AUTOSAR XML (schema 4-2-1)
standard types defined: boolean, float32, uint8, boolean_CompuMethod, boolean_DataConstr, float32_DataConstr, uint8_DataConstr
package /ComponentTypes
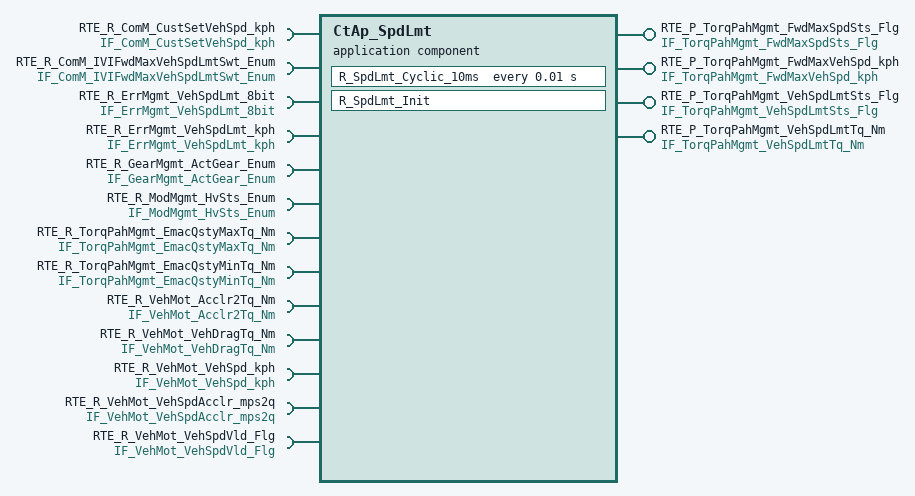
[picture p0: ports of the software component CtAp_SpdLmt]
  application sw component type CtAp_SpdLmt
    4 x provide port:
      RTE_P_TorqPahMgmt_FwdMaxSpdSts_Flg: nonqueued-sender-com-spec{data-element=tec_TorqPahMgmt_FwdMaxSpdSts_Flg, init-value=0}, provided-interface=IF_TorqPahMgmt_FwdMaxSpdSts_Flg
      RTE_P_TorqPahMgmt_FwdMaxVehSpd_kph: nonqueued-sender-com-spec{data-element=tec_TorqPahMgmt_FwdMaxVehSpd_kph, init-value=0}, provided-interface=IF_TorqPahMgmt_FwdMaxVehSpd_kph
      RTE_P_TorqPahMgmt_VehSpdLmtSts_Flg: nonqueued-sender-com-spec{data-element=tec_TorqPahMgmt_VehSpdLmtSts_Flg, init-value=0}, provided-interface=IF_TorqPahMgmt_VehSpdLmtSts_Flg
      RTE_P_TorqPahMgmt_VehSpdLmtTq_Nm: nonqueued-sender-com-spec{data-element=tec_TorqPahMgmt_VehSpdLmtTq_Nm, init-value=0}, provided-interface=IF_TorqPahMgmt_VehSpdLmtTq_Nm
    13 x require port:
      RTE_R_ComM_CustSetVehSpd_kph: nonqueued-receiver-com-spec{data-element=tec_ComM_IVISetFwdVehSpd_kph, filter=data-filter-type=ALWAYS, init-value=0}, required-interface=IF_ComM_CustSetVehSpd_kph
      RTE_R_ComM_IVIFwdMaxVehSpdLmtSwt_Enum: nonqueued-receiver-com-spec{data-element=tec_ComM_IVIFwdMaxVehSpdLmtSwt_Enum, filter=data-filter-type=ALWAYS, init-value=0}, required-interface=IF_ComM_IVIFwdMaxVehSpdLmtSwt_Enum
      RTE_R_ErrMgmt_VehSpdLmt_8bit: nonqueued-receiver-com-spec{data-element=tec_ErrMgmt_VehSpdLmt_8bit, filter=data-filter-type=ALWAYS, init-value=0}, required-interface=IF_ErrMgmt_VehSpdLmt_8bit
      RTE_R_ErrMgmt_VehSpdLmt_kph: nonqueued-receiver-com-spec{data-element=tec_ErrMgmt_VehSpdLmt_kph, filter=data-filter-type=ALWAYS, init-value=0}, required-interface=IF_ErrMgmt_VehSpdLmt_kph
      RTE_R_GearMgmt_ActGear_Enum: nonqueued-receiver-com-spec{data-element=tec_GearMgmt_ActGear_Enum, filter=data-filter-type=ALWAYS, init-value=0}, required-interface=IF_GearMgmt_ActGear_Enum
      RTE_R_ModMgmt_HvSts_Enum: nonqueued-receiver-com-spec{data-element=tec_ModMgmt_HvSts_Enum, filter=data-filter-type=ALWAYS, init-value=0}, required-interface=IF_ModMgmt_HvSts_Enum
      RTE_R_TorqPahMgmt_EmacQstyMaxTq_Nm: nonqueued-receiver-com-spec{data-element=tec_TorqPahMgmt_EmacQstyMaxTq_Nm, filter=data-filter-type=ALWAYS, init-value=0}, required-interface=IF_TorqPahMgmt_EmacQstyMaxTq_Nm
      RTE_R_TorqPahMgmt_EmacQstyMinTq_Nm: nonqueued-receiver-com-spec{data-element=tec_TorqPahMgmt_EmacQstyMinTq_Nm, filter=data-filter-type=ALWAYS, init-value=0}, required-interface=IF_TorqPahMgmt_EmacQstyMinTq_Nm
      RTE_R_VehMot_Acclr2Tq_Nm: nonqueued-receiver-com-spec{data-element=tec_VehMot_Acclr2Tq_Nm, filter=data-filter-type=ALWAYS, init-value=0}, required-interface=IF_VehMot_Acclr2Tq_Nm
      RTE_R_VehMot_VehDragTq_Nm: nonqueued-receiver-com-spec{data-element=tec_VehMot_VehDragTq_Nm, filter=data-filter-type=ALWAYS, init-value=0}, required-interface=IF_VehMot_VehDragTq_Nm
      RTE_R_VehMot_VehSpd_kph: nonqueued-receiver-com-spec{data-element=tec_VehMot_VehSpd_kph, filter=data-filter-type=ALWAYS, init-value=0}, required-interface=IF_VehMot_VehSpd_kph
      RTE_R_VehMot_VehSpdAcclr_mps2q: nonqueued-receiver-com-spec{data-element=tec_VehMot_VehSpdAcclr_mps2q, filter=data-filter-type=ALWAYS, init-value=0}, required-interface=IF_VehMot_VehSpdAcclr_mps2q
      RTE_R_VehMot_VehSpdVld_Flg: nonqueued-receiver-com-spec{data-element=tec_VehMot_VehSpdVld_Flg, filter=data-filter-type=ALWAYS, init-value=0}, required-interface=IF_VehMot_VehSpdVld_Flg
    behavior CtAp_SpdLmt_InternalBehavior
      timing event TMT_R_SpdLmt_Cyclic_10ms: start-on-event=R_SpdLmt_Cyclic_10ms, period=0.01
      init event CtAp_TorqLmt_InitEvent: start-on-event=R_SpdLmt_Init
      runnable R_SpdLmt_Cyclic_10ms
        data-receive-point-by-arguments:
          13 x access:
            REC_RTE_R_ComM_CustSetVehSpd_kph_tec_ComM_IVISetFwdVehSpd_kph: accessed-variable=RTE_R_ComM_CustSetVehSpd_kph.tec_ComM_IVISetFwdVehSpd_kph
            REC_RTE_R_ComM_IVIFwdMaxVehSpdLmtSwt_Enum_tec_ComM_IVIFwdMaxVehSpdLmtSwt_Enum: accessed-variable=RTE_R_ComM_IVIFwdMaxVehSpdLmtSwt_Enum.tec_ComM_IVIFwdMaxVehSpdLmtSwt_Enum
            REC_RTE_R_ErrMgmt_VehSpdLmt_8bit_tec_ErrMgmt_VehSpdLmt_8bit: accessed-variable=RTE_R_ErrMgmt_VehSpdLmt_8bit.tec_ErrMgmt_VehSpdLmt_8bit
            REC_RTE_R_ErrMgmt_VehSpdLmt_kph_tec_ErrMgmt_VehSpdLmt_kph: accessed-variable=RTE_R_ErrMgmt_VehSpdLmt_kph.tec_ErrMgmt_VehSpdLmt_kph
            REC_RTE_R_GearMgmt_ActGear_Enum_tec_GearMgmt_ActGear_Enum: accessed-variable=RTE_R_GearMgmt_ActGear_Enum.tec_GearMgmt_ActGear_Enum
            REC_RTE_R_ModMgmt_HvSts_Enum_tec_ModMgmt_HvSts_Enum: accessed-variable=RTE_R_ModMgmt_HvSts_Enum.tec_ModMgmt_HvSts_Enum
            REC_RTE_R_VehMot_Acclr2Tq_Nm_tec_VehMot_Acclr2Tq_Nm: accessed-variable=RTE_R_VehMot_Acclr2Tq_Nm.tec_VehMot_Acclr2Tq_Nm
            REC_RTE_R_VehMot_VehDragTq_Nm_tec_VehMot_VehDragTq_Nm: accessed-variable=RTE_R_VehMot_VehDragTq_Nm.tec_VehMot_VehDragTq_Nm
            REC_RTE_R_VehMot_VehSpd_kph_tec_VehMot_VehSpd_kph: accessed-variable=RTE_R_VehMot_VehSpd_kph.tec_VehMot_VehSpd_kph
            REC_RTE_R_VehMot_VehSpdAcclr_mps2q_tec_VehMot_VehSpdAcclr_mps2q: accessed-variable=RTE_R_VehMot_VehSpdAcclr_mps2q.tec_VehMot_VehSpdAcclr_mps2q
            REC_RTE_R_VehMot_VehSpdVld_Flg_tec_VehMot_VehSpdVld_Flg: accessed-variable=RTE_R_VehMot_VehSpdVld_Flg.tec_VehMot_VehSpdVld_Flg
            SEND_RTE_P_TorqPahMgmt_EmacQstyMaxTq_Nm_tec_TorqPahMgmt_EmacQstyMaxTq_Nm: accessed-variable=RTE_R_TorqPahMgmt_EmacQstyMaxTq_Nm.tec_TorqPahMgmt_EmacQstyMaxTq_Nm
            SEND_RTE_P_TorqPahMgmt_EmacQstyMinTq_Nm_tec_TorqPahMgmt_EmacQstyMinTq_Nm: accessed-variable=RTE_R_TorqPahMgmt_EmacQstyMinTq_Nm.tec_TorqPahMgmt_EmacQstyMinTq_Nm
        data-send-points:
          4 x access:
            SEND_RTE_P_TorqPahMgmt_FwdMaxSpdSts_Flg_tec_TorqPahMgmt_FwdMaxSpdSts_Flg: accessed-variable=RTE_P_TorqPahMgmt_FwdMaxSpdSts_Flg.tec_TorqPahMgmt_FwdMaxSpdSts_Flg
            SEND_RTE_P_TorqPahMgmt_FwdMaxVehSpd_kph_tec_TorqPahMgmt_FwdMaxVehSpd_kph: accessed-variable=RTE_P_TorqPahMgmt_FwdMaxVehSpd_kph.tec_TorqPahMgmt_FwdMaxVehSpd_kph
            SEND_RTE_P_TorqPahMgmt_VehSpdLmtSts_Flg_tec_TorqPahMgmt_VehSpdLmtSts_Flg: accessed-variable=RTE_P_TorqPahMgmt_VehSpdLmtSts_Flg.tec_TorqPahMgmt_VehSpdLmtSts_Flg
            SEND_RTE_P_TorqPahMgmt_VehSpdLmtTq_Nm_tec_TorqPahMgmt_VehSpdLmtTq_Nm: accessed-variable=RTE_P_TorqPahMgmt_VehSpdLmtTq_Nm.tec_TorqPahMgmt_VehSpdLmtTq_Nm
      runnable R_SpdLmt_Init
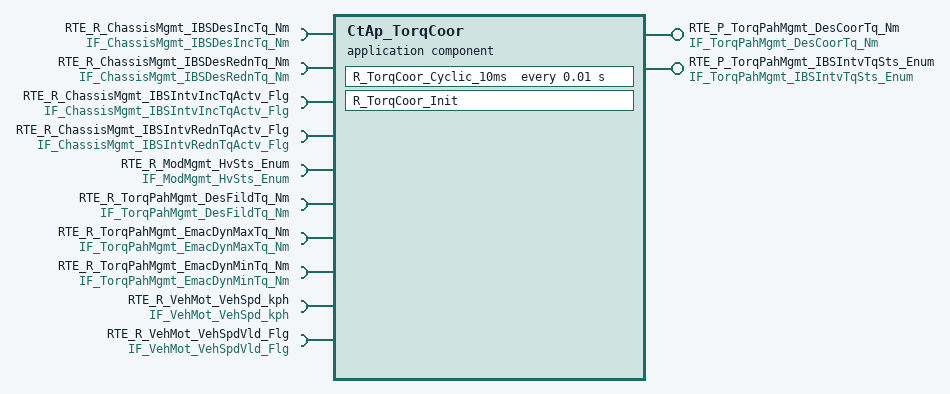
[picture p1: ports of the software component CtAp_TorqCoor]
  application sw component type CtAp_TorqCoor
    provide port RTE_P_TorqPahMgmt_DesCoorTq_Nm: nonqueued-sender-com-spec{data-element=tec_TorqPahMgmt_DesCoorTq_Nm, init-value=0}, provided-interface=IF_TorqPahMgmt_DesCoorTq_Nm
    provide port RTE_P_TorqPahMgmt_IBSIntvTqSts_Enum: nonqueued-sender-com-spec{data-element=tec_TorqPahMgmt_IBSIntvTqSts_Enum, init-value=0}, provided-interface=IF_TorqPahMgmt_IBSIntvTqSts_Enum
    10 x require port:
      RTE_R_ChassisMgmt_IBSDesIncTq_Nm: nonqueued-receiver-com-spec{data-element=tec_ChassisMgmt_IBSDesIncTq_Nm, filter=data-filter-type=ALWAYS, init-value=0}, required-interface=IF_ChassisMgmt_IBSDesIncTq_Nm
      RTE_R_ChassisMgmt_IBSDesRednTq_Nm: nonqueued-receiver-com-spec{data-element=tec_ChassisMgmt_IBSDesRednTq_Nm, filter=data-filter-type=ALWAYS, init-value=0}, required-interface=IF_ChassisMgmt_IBSDesRednTq_Nm
      RTE_R_ChassisMgmt_IBSIntvIncTqActv_Flg: nonqueued-receiver-com-spec{data-element=tec_ChassisMgmt_IBSIntvIncTqActv_Flg, filter=data-filter-type=ALWAYS, init-value=0}, required-interface=IF_ChassisMgmt_IBSIntvIncTqActv_Flg
      RTE_R_ChassisMgmt_IBSIntvRednTqActv_Flg: nonqueued-receiver-com-spec{data-element=tec_ChassisMgmt_IBSIntvRednTqActv_Flg, filter=data-filter-type=ALWAYS, init-value=0}, required-interface=IF_ChassisMgmt_IBSIntvRednTqActv_Flg
      RTE_R_ModMgmt_HvSts_Enum: nonqueued-receiver-com-spec{data-element=tec_ModMgmt_HvSts_Enum, filter=data-filter-type=ALWAYS, init-value=0}, required-interface=IF_ModMgmt_HvSts_Enum
      RTE_R_TorqPahMgmt_DesFildTq_Nm: nonqueued-receiver-com-spec{data-element=tec_TorqPahMgmt_DesFildTq_Nm, filter=data-filter-type=ALWAYS, init-value=0}, required-interface=IF_TorqPahMgmt_DesFildTq_Nm
      RTE_R_TorqPahMgmt_EmacDynMaxTq_Nm: nonqueued-receiver-com-spec{data-element=tec_TorqPahMgmt_EmacDynMaxTq_Nm, filter=data-filter-type=ALWAYS, init-value=0}, required-interface=IF_TorqPahMgmt_EmacDynMaxTq_Nm
      RTE_R_TorqPahMgmt_EmacDynMinTq_Nm: nonqueued-receiver-com-spec{data-element=tec_TorqPahMgmt_EmacDynMinTq_Nm, filter=data-filter-type=ALWAYS, init-value=0}, required-interface=IF_TorqPahMgmt_EmacDynMinTq_Nm
      RTE_R_VehMot_VehSpd_kph: nonqueued-receiver-com-spec{data-element=tec_VehMot_VehSpd_kph, filter=data-filter-type=ALWAYS, init-value=0}, required-interface=IF_VehMot_VehSpd_kph
      RTE_R_VehMot_VehSpdVld_Flg: nonqueued-receiver-com-spec{data-element=tec_VehMot_VehSpdVld_Flg, filter=data-filter-type=ALWAYS, init-value=0}, required-interface=IF_VehMot_VehSpdVld_Flg
    behavior CtAp_TorqCoor_InternalBehavior
      timing event TMT_R_TorqCoor_Cyclic_10ms: start-on-event=R_TorqCoor_Cyclic_10ms, period=0.01
      init event CtAp_TorqCoor_InitEvent: start-on-event=R_TorqCoor_Init
      runnable R_TorqCoor_Cyclic_10ms
        data-receive-point-by-arguments:
          10 x access:
            REC_RTE_R_ChassisMgmt_IBSDesIncTq_Nm_tec_ChassisMgmt_IBSDesIncTq_Nm: accessed-variable=RTE_R_ChassisMgmt_IBSDesIncTq_Nm.tec_ChassisMgmt_IBSDesIncTq_Nm
            REC_RTE_R_ChassisMgmt_IBSDesRednTq_Nm_tec_ChassisMgmt_IBSDesRednTq_Nm: accessed-variable=RTE_R_ChassisMgmt_IBSDesRednTq_Nm.tec_ChassisMgmt_IBSDesRednTq_Nm
            REC_RTE_R_ChassisMgmt_IBSIntvIncTqActv_Flg_tec_ChassisMgmt_IBSIntvIncTqActv_Flg: accessed-variable=RTE_R_ChassisMgmt_IBSIntvIncTqActv_Flg.tec_ChassisMgmt_IBSIntvIncTqActv_Flg
            REC_RTE_R_ChassisMgmt_IBSIntvRednTqActv_Flg_tec_ChassisMgmt_IBSIntvRednTqActv_Flg: accessed-variable=RTE_R_ChassisMgmt_IBSIntvRednTqActv_Flg.tec_ChassisMgmt_IBSIntvRednTqActv_Flg
            REC_RTE_R_ModMgmt_HvSts_Enum_tec_ModMgmt_HvSts_Enum: accessed-variable=RTE_R_ModMgmt_HvSts_Enum.tec_ModMgmt_HvSts_Enum
            REC_RTE_R_TorqPahMgmt_DesFildTq_Nm_tec_TorqPahMgmt_DesFildTq_Nm: accessed-variable=RTE_R_TorqPahMgmt_DesFildTq_Nm.tec_TorqPahMgmt_DesFildTq_Nm
            REC_RTE_R_TorqPahMgmt_EmacDynMaxTq_Nm_tec_TorqPahMgmt_EmacDynMaxTq_Nm: accessed-variable=RTE_R_TorqPahMgmt_EmacDynMaxTq_Nm.tec_TorqPahMgmt_EmacDynMaxTq_Nm
            REC_RTE_R_TorqPahMgmt_EmacDynMinTq_Nm_tec_TorqPahMgmt_EmacDynMinTq_Nm: accessed-variable=RTE_R_TorqPahMgmt_EmacDynMinTq_Nm.tec_TorqPahMgmt_EmacDynMinTq_Nm
            REC_RTE_R_VehMot_VehSpd_kph_tec_VehMot_VehSpd_kph: accessed-variable=RTE_R_VehMot_VehSpd_kph.tec_VehMot_VehSpd_kph
            REC_RTE_R_VehMot_VehSpdVld_Flg_tec_VehMot_VehSpdVld_Flg: accessed-variable=RTE_R_VehMot_VehSpdVld_Flg.tec_VehMot_VehSpdVld_Flg
        data-send-points:
          access SEND_RTE_P_TorqPahMgmt_DesCoorTq_Nm_tec_TorqPahMgmt_DesCoorTq_Nm: accessed-variable=RTE_P_TorqPahMgmt_DesCoorTq_Nm.tec_TorqPahMgmt_DesCoorTq_Nm
          access SEND_RTE_P_TorqPahMgmt_IBSIntvTqSts_Enum_tec_TorqPahMgmt_IBSIntvTqSts_Enum: accessed-variable=RTE_P_TorqPahMgmt_IBSIntvTqSts_Enum.tec_TorqPahMgmt_IBSIntvTqSts_Enum
      runnable R_TorqCoor_Init
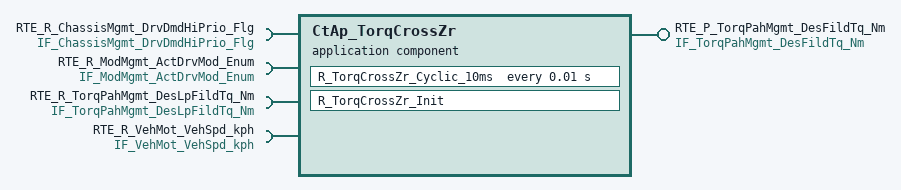
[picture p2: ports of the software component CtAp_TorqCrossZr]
  application sw component type CtAp_TorqCrossZr
    provide port RTE_P_TorqPahMgmt_DesFildTq_Nm: nonqueued-sender-com-spec{data-element=tec_TorqPahMgmt_DesFildTq_Nm, init-value=0}, provided-interface=IF_TorqPahMgmt_DesFildTq_Nm
    4 x require port:
      RTE_R_ChassisMgmt_DrvDmdHiPrio_Flg: nonqueued-receiver-com-spec{data-element=tec_ChassisMgmt_DrvDmdHiPrio_Flg, filter=data-filter-type=ALWAYS, init-value=0}, required-interface=IF_ChassisMgmt_DrvDmdHiPrio_Flg
      RTE_R_ModMgmt_ActDrvMod_Enum: nonqueued-receiver-com-spec{data-element=tec_ModMgmt_ActDrvMod_Enum, filter=data-filter-type=ALWAYS, init-value=0}, required-interface=IF_ModMgmt_ActDrvMod_Enum
      RTE_R_TorqPahMgmt_DesLpFildTq_Nm: nonqueued-receiver-com-spec{data-element=tec_TorqPahMgmt_DesLpFildTq_Nm, filter=data-filter-type=ALWAYS, init-value=0}, required-interface=IF_TorqPahMgmt_DesLpFildTq_Nm
      RTE_R_VehMot_VehSpd_kph: nonqueued-receiver-com-spec{data-element=tec_VehMot_VehSpd_kph, filter=data-filter-type=ALWAYS, init-value=0}, required-interface=IF_VehMot_VehSpd_kph
    behavior CtAp_TorqCrossZr_InternalBehavior
      timing event TMT_R_TorqCrossZr_Cyclic_10ms: start-on-event=R_TorqCrossZr_Cyclic_10ms, period=0.01
      init event CtAp_TorqCrossZr_InitEvent: start-on-event=R_TorqCrossZr_Init
      runnable R_TorqCrossZr_Cyclic_10ms
        data-receive-point-by-arguments:
          4 x access:
            REC_RTE_R_ChassisMgmt_DrvDmdHiPrio_Flg_tec_ChassisMgmt_DrvDmdHiPrio_Flg: accessed-variable=RTE_R_ChassisMgmt_DrvDmdHiPrio_Flg.tec_ChassisMgmt_DrvDmdHiPrio_Flg
            REC_RTE_R_ModMgmt_ActDrvMod_Enum_tec_ModMgmt_ActDrvMod_Enum: accessed-variable=RTE_R_ModMgmt_ActDrvMod_Enum.tec_ModMgmt_ActDrvMod_Enum
            REC_RTE_R_TorqPahMgmt_DesLpFildTq_Nm_tec_TorqPahMgmt_DesLpFildTq_Nm: accessed-variable=RTE_R_TorqPahMgmt_DesLpFildTq_Nm.tec_TorqPahMgmt_DesLpFildTq_Nm
            REC_RTE_R_VehMot_VehSpd_kph_tec_VehMot_VehSpd_kph: accessed-variable=RTE_R_VehMot_VehSpd_kph.tec_VehMot_VehSpd_kph
        data-send-points:
          access SEND_RTE_P_TorqPahMgmt_DesFildTq_Nm_tec_TorqPahMgmt_DesFildTq_Nm: accessed-variable=RTE_P_TorqPahMgmt_DesFildTq_Nm.tec_TorqPahMgmt_DesFildTq_Nm
      runnable R_TorqCrossZr_Init
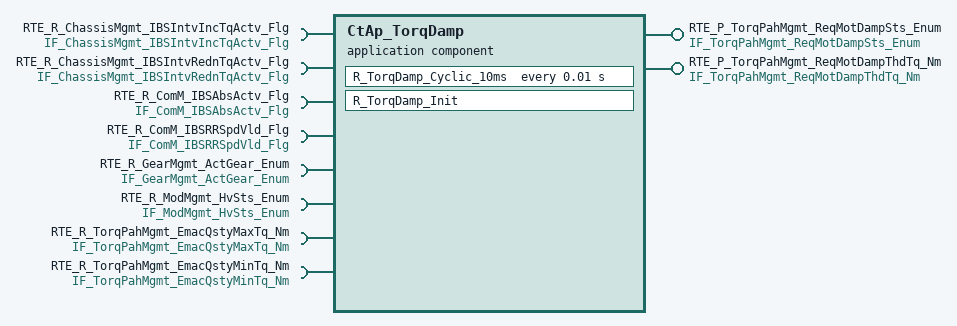
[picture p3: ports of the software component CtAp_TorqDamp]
  application sw component type CtAp_TorqDamp
    provide port RTE_P_TorqPahMgmt_ReqMotDampSts_Enum: nonqueued-sender-com-spec=data-element=tec_TorqPahMgmt_ReqMotDampSts_Enum, provided-interface=IF_TorqPahMgmt_ReqMotDampSts_Enum
    provide port RTE_P_TorqPahMgmt_ReqMotDampThdTq_Nm: nonqueued-sender-com-spec=data-element=tec_TorqPahMgmt_ReqMotDampThdTq_Nm, provided-interface=IF_TorqPahMgmt_ReqMotDampThdTq_Nm
    8 x require port:
      RTE_R_ChassisMgmt_IBSIntvIncTqActv_Flg: nonqueued-receiver-com-spec{data-element=tec_ChassisMgmt_IBSIntvIncTqActv_Flg, filter=data-filter-type=ALWAYS}, required-interface=IF_ChassisMgmt_IBSIntvIncTqActv_Flg
      RTE_R_ChassisMgmt_IBSIntvRednTqActv_Flg: nonqueued-receiver-com-spec{data-element=tec_ChassisMgmt_IBSIntvRednTqActv_Flg, filter=data-filter-type=ALWAYS}, required-interface=IF_ChassisMgmt_IBSIntvRednTqActv_Flg
      RTE_R_ComM_IBSAbsActv_Flg: nonqueued-receiver-com-spec{data-element=tec_ComM_IBSAbsActv_Flg, filter=data-filter-type=ALWAYS}, required-interface=IF_ComM_IBSAbsActv_Flg
      RTE_R_ComM_IBSRRSpdVld_Flg: nonqueued-receiver-com-spec{data-element=tec_ComM_IBSRRSpdVld_Flg, filter=data-filter-type=ALWAYS}, required-interface=IF_ComM_IBSRRSpdVld_Flg
      RTE_R_GearMgmt_ActGear_Enum: nonqueued-receiver-com-spec{data-element=tec_GearMgmt_ActGear_Enum, filter=data-filter-type=ALWAYS}, required-interface=IF_GearMgmt_ActGear_Enum
      RTE_R_ModMgmt_HvSts_Enum: nonqueued-receiver-com-spec{data-element=tec_ModMgmt_HvSts_Enum, filter=data-filter-type=ALWAYS}, required-interface=IF_ModMgmt_HvSts_Enum
      RTE_R_TorqPahMgmt_EmacQstyMaxTq_Nm: nonqueued-receiver-com-spec{data-element=tec_TorqPahMgmt_EmacQstyMaxTq_Nm, filter=data-filter-type=ALWAYS}, required-interface=IF_TorqPahMgmt_EmacQstyMaxTq_Nm
      RTE_R_TorqPahMgmt_EmacQstyMinTq_Nm: nonqueued-receiver-com-spec{data-element=tec_TorqPahMgmt_EmacQstyMinTq_Nm, filter=data-filter-type=ALWAYS}, required-interface=IF_TorqPahMgmt_EmacQstyMinTq_Nm
    behavior CtAp_TorqDamp_InternalBehavior
      timing event TMT_R_TorqDamp_Cyclic_10ms: start-on-event=R_TorqDamp_Cyclic_10ms, period=0.01
      init event CtAp_TorqDamp_InitEvent: start-on-event=R_TorqDamp_Init
      runnable R_TorqDamp_Cyclic_10ms
        data-receive-point-by-arguments:
          8 x access:
            REC_RTE_R_ChassisMgmt_IBSIntvIncTqActv_Flg_tec_ChassisMgmt_IBSIntvIncTqActv_Flg: accessed-variable=RTE_R_ChassisMgmt_IBSIntvIncTqActv_Flg.tec_ChassisMgmt_IBSIntvIncTqActv_Flg
            REC_RTE_R_ChassisMgmt_IBSIntvRednTqActv_Flg_tec_ChassisMgmt_IBSIntvRednTqActv_Flg: accessed-variable=RTE_R_ChassisMgmt_IBSIntvRednTqActv_Flg.tec_ChassisMgmt_IBSIntvRednTqActv_Flg
            REC_RTE_R_ComM_IBSAbsActv_Flg_tec_ComM_IBSAbsActv_Flg: accessed-variable=RTE_R_ComM_IBSAbsActv_Flg.tec_ComM_IBSAbsActv_Flg
            REC_RTE_R_Comm_IBSRRSpdVld_Flg_tec_ComM_IBSRRSpdVld_Flg: accessed-variable=RTE_R_ComM_IBSRRSpdVld_Flg.tec_ComM_IBSRRSpdVld_Flg
            REC_RTE_R_GearMgmt_ActGear_Enum_tec_GearMgmt_ActGear_Enum: accessed-variable=RTE_R_GearMgmt_ActGear_Enum.tec_GearMgmt_ActGear_Enum
            REC_RTE_R_ModMgmt_HvSts_Enum_tec_ModMgmt_HvSts_Enum: accessed-variable=RTE_R_ModMgmt_HvSts_Enum.tec_ModMgmt_HvSts_Enum
            REC_RTE_R_TorqPahMgmt_EmacQstyMaxTq_Nm_tec_TorqPahMgmt_EmacQstyMaxTq_Nm: accessed-variable=RTE_R_TorqPahMgmt_EmacQstyMaxTq_Nm.tec_TorqPahMgmt_EmacQstyMaxTq_Nm
            REC_RTE_R_TorqPahMgmt_EmacQstyMinTq_Nm_tec_TorqPahMgmt_EmacQstyMinTq_Nm: accessed-variable=RTE_R_TorqPahMgmt_EmacQstyMinTq_Nm.tec_TorqPahMgmt_EmacQstyMinTq_Nm
        data-send-points:
          access SEND_RTE_P_TorqPahMgmt_ReqMotDampSts_Enum_tec_TorqPahMgmt_ReqMotDampSts_Enum: accessed-variable=RTE_P_TorqPahMgmt_ReqMotDampSts_Enum.tec_TorqPahMgmt_ReqMotDampSts_Enum
          access SEND_RTE_P_TorqPahMgmt_ReqMotDampThdTq_Nm_tec_TorqPahMgmt_ReqMotDampThdTq_Nm: accessed-variable=RTE_P_TorqPahMgmt_ReqMotDampThdTq_Nm.tec_TorqPahMgmt_ReqMotDampThdTq_Nm
      runnable R_TorqDamp_Init
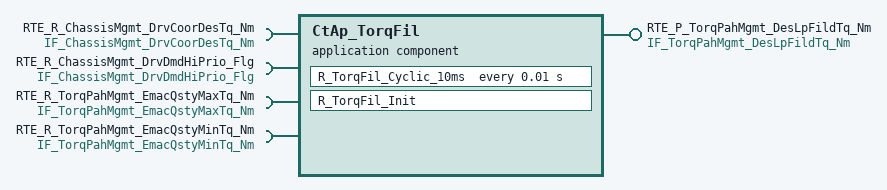
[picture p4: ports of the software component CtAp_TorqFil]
  application sw component type CtAp_TorqFil
    provide port RTE_P_TorqPahMgmt_DesLpFildTq_Nm: nonqueued-sender-com-spec{data-element=tec_TorqPahMgmt_DesLpFildTq_Nm, init-value=0}, provided-interface=IF_TorqPahMgmt_DesLpFildTq_Nm
    4 x require port:
      RTE_R_ChassisMgmt_DrvCoorDesTq_Nm: nonqueued-receiver-com-spec{data-element=tec_ChassisMgmt_DrvCoorDesTq_Nm, filter=data-filter-type=ALWAYS, init-value=0}, required-interface=IF_ChassisMgmt_DrvCoorDesTq_Nm
      RTE_R_ChassisMgmt_DrvDmdHiPrio_Flg: nonqueued-receiver-com-spec{data-element=tec_ChassisMgmt_DrvDmdHiPrio_Flg, filter=data-filter-type=ALWAYS, init-value=0}, required-interface=IF_ChassisMgmt_DrvDmdHiPrio_Flg
      RTE_R_TorqPahMgmt_EmacQstyMaxTq_Nm: nonqueued-receiver-com-spec{data-element=tec_TorqPahMgmt_EmacQstyMaxTq_Nm, filter=data-filter-type=ALWAYS, init-value=0}, required-interface=IF_TorqPahMgmt_EmacQstyMaxTq_Nm
      RTE_R_TorqPahMgmt_EmacQstyMinTq_Nm: nonqueued-receiver-com-spec{data-element=tec_TorqPahMgmt_EmacQstyMinTq_Nm, filter=data-filter-type=ALWAYS, init-value=0}, required-interface=IF_TorqPahMgmt_EmacQstyMinTq_Nm
    behavior CtAp_TorqFil_InternalBehavior
      timing event TMT_R_TorqFil_Cyclic_10ms: start-on-event=R_TorqFil_Cyclic_10ms, period=0.01
      init event CtAp_TorqFil_InitEvent: start-on-event=R_TorqFil_Init
      runnable R_TorqFil_Cyclic_10ms
        data-receive-point-by-arguments:
          4 x access:
            REC_RTE_R_ChassisMgmt_DrvCoorDesTq_Nm_tec_ChassisMgmt_DrvCoorDesTq_Nm: accessed-variable=RTE_R_ChassisMgmt_DrvCoorDesTq_Nm.tec_ChassisMgmt_DrvCoorDesTq_Nm
            REC_RTE_R_ChassisMgmt_DrvDmdHiPrio_Flg_tec_ChassisMgmt_DrvDmdHiPrio_Flg: accessed-variable=RTE_R_ChassisMgmt_DrvDmdHiPrio_Flg.tec_ChassisMgmt_DrvDmdHiPrio_Flg
            REC_RTE_R_TorqPahMgmt_EmacQstyMaxTq_Nm_tec_TorqPahMgmt_EmacQstyMaxTq_Nm: accessed-variable=RTE_R_TorqPahMgmt_EmacQstyMaxTq_Nm.tec_TorqPahMgmt_EmacQstyMaxTq_Nm
            REC_RTE_R_TorqPahMgmt_EmacQstyMinTq_Nm_tec_TorqPahMgmt_EmacQstyMinTq_Nm: accessed-variable=RTE_R_TorqPahMgmt_EmacQstyMinTq_Nm.tec_TorqPahMgmt_EmacQstyMinTq_Nm
        data-send-points:
          access SEND_RTE_P_TorqPahMgmt_DesLpFildTq_Nm_tec_TorqPahMgmt_DesLpFildTq_Nm: accessed-variable=RTE_P_TorqPahMgmt_DesLpFildTq_Nm.tec_TorqPahMgmt_DesLpFildTq_Nm
      runnable R_TorqFil_Init
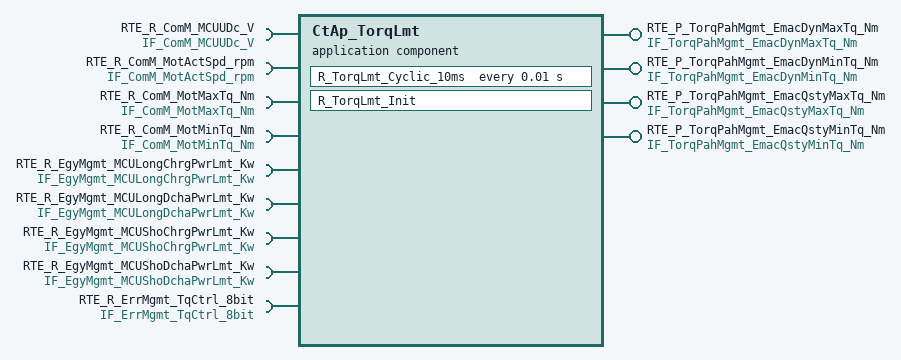
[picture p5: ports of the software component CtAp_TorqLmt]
  application sw component type CtAp_TorqLmt
    4 x provide port:
      RTE_P_TorqPahMgmt_EmacDynMaxTq_Nm: nonqueued-sender-com-spec{data-element=tec_TorqPahMgmt_EmacDynMaxTq_Nm, init-value=0}, provided-interface=IF_TorqPahMgmt_EmacDynMaxTq_Nm
      RTE_P_TorqPahMgmt_EmacDynMinTq_Nm: nonqueued-sender-com-spec{data-element=tec_TorqPahMgmt_EmacDynMinTq_Nm, init-value=0}, provided-interface=IF_TorqPahMgmt_EmacDynMinTq_Nm
      RTE_P_TorqPahMgmt_EmacQstyMaxTq_Nm: nonqueued-sender-com-spec{data-element=tec_TorqPahMgmt_EmacQstyMaxTq_Nm, init-value=0}, provided-interface=IF_TorqPahMgmt_EmacQstyMaxTq_Nm
      RTE_P_TorqPahMgmt_EmacQstyMinTq_Nm: nonqueued-sender-com-spec{data-element=tec_TorqPahMgmt_EmacQstyMinTq_Nm, init-value=0}, provided-interface=IF_TorqPahMgmt_EmacQstyMinTq_Nm
    9 x require port:
      RTE_R_ComM_MCUUDc_V: nonqueued-receiver-com-spec{data-element=tec_ComM_MCUUDc_V, filter=data-filter-type=ALWAYS, init-value=0}, required-interface=IF_ComM_MCUUDc_V
      RTE_R_ComM_MotActSpd_rpm: nonqueued-receiver-com-spec{data-element=tec_ComM_MotActSpd_rpm, filter=data-filter-type=ALWAYS, init-value=0}, required-interface=IF_ComM_MotActSpd_rpm
      RTE_R_ComM_MotMaxTq_Nm: nonqueued-receiver-com-spec{data-element=tec_ComM_MotMaxTq_Nm, filter=data-filter-type=ALWAYS, init-value=0}, required-interface=IF_ComM_MotMaxTq_Nm
      RTE_R_ComM_MotMinTq_Nm: nonqueued-receiver-com-spec{data-element=tec_ComM_MotMinTq_Nm, filter=data-filter-type=ALWAYS, init-value=0}, required-interface=IF_ComM_MotMinTq_Nm
      RTE_R_EgyMgmt_MCULongChrgPwrLmt_Kw: nonqueued-receiver-com-spec{data-element=tec_EgyMgmt_MCULongChrgPwrLmt_Kw, filter=data-filter-type=ALWAYS, init-value=0}, required-interface=IF_EgyMgmt_MCULongChrgPwrLmt_Kw
      RTE_R_EgyMgmt_MCULongDchaPwrLmt_Kw: nonqueued-receiver-com-spec{data-element=tec_EgyMgmt_MCULongDchaPwrLmt_Kw, filter=data-filter-type=ALWAYS, init-value=0}, required-interface=IF_EgyMgmt_MCULongDchaPwrLmt_Kw
      RTE_R_EgyMgmt_MCUShoChrgPwrLmt_Kw: nonqueued-receiver-com-spec{data-element=tec_EgyMgmt_MCUShoChrgPwrLmt_Kw, filter=data-filter-type=ALWAYS, init-value=0}, required-interface=IF_EgyMgmt_MCUShoChrgPwrLmt_Kw
      RTE_R_EgyMgmt_MCUShoDchaPwrLmt_Kw: nonqueued-receiver-com-spec{data-element=tec_EgyMgmt_MCUShoDchaPwrLmt_Kw, filter=data-filter-type=ALWAYS, init-value=0}, required-interface=IF_EgyMgmt_MCUShoDchaPwrLmt_Kw
      RTE_R_ErrMgmt_TqCtrl_8bit: nonqueued-receiver-com-spec{data-element=tec_ErrMgmt_TqCtrl_8bit, filter=data-filter-type=ALWAYS, init-value=0}, required-interface=IF_ErrMgmt_TqCtrl_8bit
    behavior CtAp_TorqLmt_InternalBehavior
      timing event TMT_R_TorqLmt_Cyclic_10ms: start-on-event=R_TorqLmt_Cyclic_10ms, period=0.01
      init event CtAp_TorqLmt_InitEvent: start-on-event=R_TorqLmt_Init
      runnable R_TorqLmt_Cyclic_10ms
        data-receive-point-by-arguments:
          9 x access:
            REC_RTE_R_ComM_MCUUDc_V_tec_ComM_MCUUDc_V: accessed-variable=RTE_R_ComM_MCUUDc_V.tec_ComM_MCUUDc_V
            REC_RTE_R_ComM_MotActSpd_rpm_tec_ComM_MotActSpd_rpm: accessed-variable=RTE_R_ComM_MotActSpd_rpm.tec_ComM_MotActSpd_rpm
            REC_RTE_R_ComM_MotMaxTq_Nm_tec_ComM_MotMaxTq_Nm: accessed-variable=RTE_R_ComM_MotMaxTq_Nm.tec_ComM_MotMaxTq_Nm
            REC_RTE_R_ComM_MotMinTq_Nm_tec_ComM_MotMinTq_Nm: accessed-variable=RTE_R_ComM_MotMinTq_Nm.tec_ComM_MotMinTq_Nm
            REC_RTE_R_EgyMgmt_MCULongChrgPwrLmt_Kw_tec_EgyMgmt_MCULongChrgPwrLmt_Kw: accessed-variable=RTE_R_EgyMgmt_MCULongChrgPwrLmt_Kw.tec_EgyMgmt_MCULongChrgPwrLmt_Kw
            REC_RTE_R_EgyMgmt_MCULongDchaPwrLmt_Kw_tec_EgyMgmt_MCULongDchaPwrLmt_Kw: accessed-variable=RTE_R_EgyMgmt_MCULongDchaPwrLmt_Kw.tec_EgyMgmt_MCULongDchaPwrLmt_Kw
            REC_RTE_R_EgyMgmt_MCUShoChrgPwrLmt_Kw_tec_EgyMgmt_MCUShoChrgPwrLmt_Kw: accessed-variable=RTE_R_EgyMgmt_MCUShoChrgPwrLmt_Kw.tec_EgyMgmt_MCUShoChrgPwrLmt_Kw
            REC_RTE_R_EgyMgmt_MCUShoDchaPwrLmt_Kw_tec_EgyMgmt_MCUShoDchaPwrLmt_Kw: accessed-variable=RTE_R_EgyMgmt_MCUShoDchaPwrLmt_Kw.tec_EgyMgmt_MCUShoDchaPwrLmt_Kw
            REC_RTE_R_ErrMgmt_TqCtrl_8bit_tec_ErrMgmt_TqCtrl_8bit: accessed-variable=RTE_R_ErrMgmt_TqCtrl_8bit.tec_ErrMgmt_TqCtrl_8bit
        data-send-points:
          4 x access:
            SEND_RTE_P_TorqPahMgmt_EmacDynMaxTq_Nm_tec_TorqPahMgmt_EmacDynMaxTq_Nm: accessed-variable=RTE_P_TorqPahMgmt_EmacDynMaxTq_Nm.tec_TorqPahMgmt_EmacDynMaxTq_Nm
            SEND_RTE_P_TorqPahMgmt_EmacDynMinTq_Nm_tec_TorqPahMgmt_EmacDynMinTq_Nm: accessed-variable=RTE_P_TorqPahMgmt_EmacDynMinTq_Nm.tec_TorqPahMgmt_EmacDynMinTq_Nm
            SEND_RTE_P_TorqPahMgmt_EmacQstyMaxTq_Nm_tec_TorqPahMgmt_EmacQstyMaxTq_Nm: accessed-variable=RTE_P_TorqPahMgmt_EmacQstyMaxTq_Nm.tec_TorqPahMgmt_EmacQstyMaxTq_Nm
            SEND_RTE_P_TorqPahMgmt_EmacQstyMinTq_Nm_tec_TorqPahMgmt_EmacQstyMinTq_Nm: accessed-variable=RTE_P_TorqPahMgmt_EmacQstyMinTq_Nm.tec_TorqPahMgmt_EmacQstyMinTq_Nm
      runnable R_TorqLmt_Init
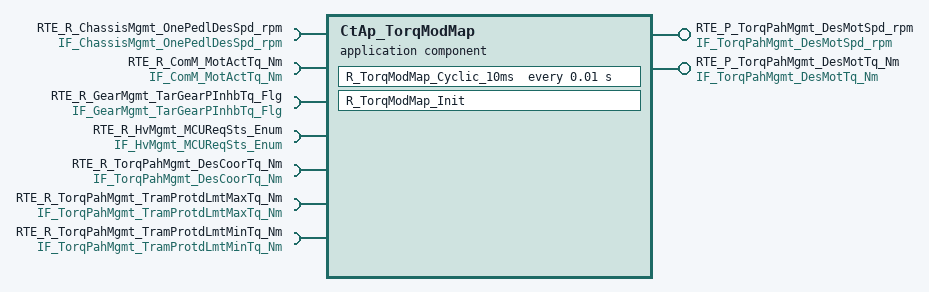
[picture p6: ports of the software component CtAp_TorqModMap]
  application sw component type CtAp_TorqModMap
    provide port RTE_P_TorqPahMgmt_DesMotSpd_rpm: nonqueued-sender-com-spec{data-element=tec_TorqPahMgmt_DesMotSpd_rpm, init-value=0}, provided-interface=IF_TorqPahMgmt_DesMotSpd_rpm
    provide port RTE_P_TorqPahMgmt_DesMotTq_Nm: nonqueued-sender-com-spec{data-element=tec_TorqPahMgmt_DesMotTq_Nm, init-value=0}, provided-interface=IF_TorqPahMgmt_DesMotTq_Nm
    7 x require port:
      RTE_R_ChassisMgmt_OnePedlDesSpd_rpm: nonqueued-receiver-com-spec{data-element=tec_ChassisMgmt_OnePedlDesSpd_rpm, filter=data-filter-type=ALWAYS, init-value=0}, required-interface=IF_ChassisMgmt_OnePedlDesSpd_rpm
      RTE_R_ComM_MotActTq_Nm: nonqueued-receiver-com-spec{data-element=tec_ComM_MotActTq_Nm, filter=data-filter-type=ALWAYS, init-value=0}, required-interface=IF_ComM_MotActTq_Nm
      RTE_R_GearMgmt_TarGearPInhbTq_Flg: nonqueued-receiver-com-spec{data-element=tec_GearMgmt_TarGearPInhbTq_Flg, filter=data-filter-type=ALWAYS, init-value=0}, required-interface=IF_GearMgmt_TarGearPInhbTq_Flg
      RTE_R_HvMgmt_MCUReqSts_Enum: nonqueued-receiver-com-spec{data-element=tec_HvMgmt_MCUReqSts_Enum, filter=data-filter-type=ALWAYS, init-value=0}, required-interface=IF_HvMgmt_MCUReqSts_Enum
      RTE_R_TorqPahMgmt_DesCoorTq_Nm: nonqueued-receiver-com-spec{data-element=tec_TorqPahMgmt_DesCoorTq_Nm, filter=data-filter-type=ALWAYS, init-value=0}, required-interface=IF_TorqPahMgmt_DesCoorTq_Nm
      RTE_R_TorqPahMgmt_TramProtdLmtMaxTq_Nm: nonqueued-receiver-com-spec{data-element=IF_TorqPahMgmt_TramProtdLmtMaxTq_Nm/tec_TorqPahMgmt_TramProtdLmtMaxTq_Nm, filter=data-filter-type=ALWAYS, init-value=0}, required-interface=IF_TorqPahMgmt_TramProtdLmtMaxTq_Nm
      RTE_R_TorqPahMgmt_TramProtdLmtMinTq_Nm: nonqueued-receiver-com-spec{data-element=IF_TorqPahMgmt_TramProtdLmtMinTq_Nm/tec_TorqPahMgmt_TramProtdLmtMinTq_Nm, filter=data-filter-type=ALWAYS, init-value=0}, required-interface=IF_TorqPahMgmt_TramProtdLmtMinTq_Nm
    behavior CtAp_TorqModMap_InternalBehavior
      timing event TMT_R_TorqModMap_Cyclic_10ms: start-on-event=R_TorqModMap_Cyclic_10ms, period=0.01
      init event CtAp_TorqModMap_InitEvent: start-on-event=R_TorqModMap_Init
      runnable R_TorqModMap_Cyclic_10ms
        data-receive-point-by-arguments:
          7 x access:
            REC_RTE_R_ChassisMgmt_OnePedlDesSpd_rpm_tec_ChassisMgmt_OnePedlDesSpd_rpm: accessed-variable=RTE_R_ChassisMgmt_OnePedlDesSpd_rpm.tec_ChassisMgmt_OnePedlDesSpd_rpm
            REC_RTE_R_ComM_MotActTq_Nm_tec_ComM_MotActTq_Nm: accessed-variable=RTE_R_ComM_MotActTq_Nm.tec_ComM_MotActTq_Nm
            REC_RTE_R_GearMgmt_TarGearPInhbTq_Flg_tec_GearMgmt_TarGearPInhbTq_Flg: accessed-variable=RTE_R_GearMgmt_TarGearPInhbTq_Flg.tec_GearMgmt_TarGearPInhbTq_Flg
            REC_RTE_R_HvMgmt_MCUReqSts_Enum_tec_HvMgmt_MCUReqSts_Enum: accessed-variable=RTE_R_HvMgmt_MCUReqSts_Enum.tec_HvMgmt_MCUReqSts_Enum
            REC_RTE_R_TorqPahMgmt_DesCoorTq_Nm_tec_TorqPahMgmt_DesCoorTq_Nm: accessed-variable=RTE_R_TorqPahMgmt_DesCoorTq_Nm.tec_TorqPahMgmt_DesCoorTq_Nm
            REC_RTE_R_TorqPahMgmt_TramProtdLmtMaxTq_Nm_tec_TorqPahMgmt_TramProtdLmtMaxTq_Nm: accessed-variable=RTE_R_TorqPahMgmt_TramProtdLmtMaxTq_Nm.tec_TorqPahMgmt_TramProtdLmtMaxTq_Nm
            REC_RTE_R_TorqPahMgmt_TramProtdLmtMinTq_Nm_tec_TorqPahMgmt_TramProtdLmtMinTq_Nm: accessed-variable=RTE_R_TorqPahMgmt_TramProtdLmtMinTq_Nm.tec_TorqPahMgmt_TramProtdLmtMinTq_Nm
        data-send-points:
          access SEND_RTE_P_TorqPahMgmt_DesMotSpd_rpm_tec_TorqPahMgmt_DesMotSpd_rpm: accessed-variable=RTE_P_TorqPahMgmt_DesMotSpd_rpm.tec_TorqPahMgmt_DesMotSpd_rpm
          access SEND_RTE_P_TorqPahMgmt_DesMotTq_Nm_tec_TorqPahMgmt_DesMotTq_Nm: accessed-variable=RTE_P_TorqPahMgmt_DesMotTq_Nm.tec_TorqPahMgmt_DesMotTq_Nm
      runnable R_TorqModMap_Init
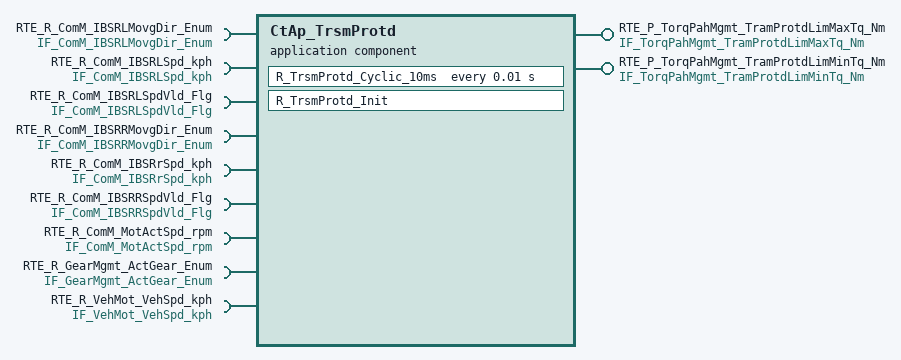
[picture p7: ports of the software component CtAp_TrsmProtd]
  application sw component type CtAp_TrsmProtd
    provide port RTE_P_TorqPahMgmt_TramProtdLimMaxTq_Nm: nonqueued-sender-com-spec{data-element=IF_TorqPahMgmt_TramProtdLimMaxTq_Nm/tec_TorqPahMgmt_TramProtdLmtMaxTq_Nm, init-value=0}, provided-interface=IF_TorqPahMgmt_TramProtdLimMaxTq_Nm
    provide port RTE_P_TorqPahMgmt_TramProtdLimMinTq_Nm: nonqueued-sender-com-spec{data-element=IF_TorqPahMgmt_TramProtdLimMinTq_Nm/tec_TorqPahMgmt_TramProtdLmtMinTq_Nm, init-value=0}, provided-interface=IF_TorqPahMgmt_TramProtdLimMinTq_Nm
    9 x require port:
      RTE_R_ComM_IBSRLMovgDir_Enum: nonqueued-receiver-com-spec{data-element=tec_ComM_IBSRLMovgDir_Enum, filter=data-filter-type=ALWAYS, init-value=0}, required-interface=IF_ComM_IBSRLMovgDir_Enum
      RTE_R_ComM_IBSRLSpd_kph: nonqueued-receiver-com-spec{data-element=tec_ComM_IBSRLSpd_kph, filter=data-filter-type=ALWAYS, init-value=0}, required-interface=IF_ComM_IBSRLSpd_kph
      RTE_R_ComM_IBSRLSpdVld_Flg: nonqueued-receiver-com-spec{data-element=tec_ComM_IBSRLSpdVld_Flg, filter=data-filter-type=ALWAYS, init-value=0}, required-interface=IF_ComM_IBSRLSpdVld_Flg
      RTE_R_ComM_IBSRRMovgDir_Enum: nonqueued-receiver-com-spec{data-element=tec_ComM_IBSRRMovgDir_Enum, filter=data-filter-type=ALWAYS, init-value=0}, required-interface=IF_ComM_IBSRRMovgDir_Enum
      RTE_R_ComM_IBSRrSpd_kph: nonqueued-receiver-com-spec{data-element=tec_ComM_IBSRRSpd_kph, filter=data-filter-type=ALWAYS, init-value=0}, required-interface=IF_ComM_IBSRrSpd_kph
      RTE_R_ComM_IBSRRSpdVld_Flg: nonqueued-receiver-com-spec{data-element=tec_ComM_IBSRRSpdVld_Flg, filter=data-filter-type=ALWAYS, init-value=0}, required-interface=IF_ComM_IBSRRSpdVld_Flg
      RTE_R_ComM_MotActSpd_rpm: nonqueued-receiver-com-spec{data-element=tec_ComM_MotActSpd_rpm, filter=data-filter-type=ALWAYS, init-value=0}, required-interface=IF_ComM_MotActSpd_rpm
      RTE_R_GearMgmt_ActGear_Enum: nonqueued-receiver-com-spec{data-element=tec_GearMgmt_ActGear_Enum, filter=data-filter-type=ALWAYS, init-value=0}, required-interface=IF_GearMgmt_ActGear_Enum
      RTE_R_VehMot_VehSpd_kph: nonqueued-receiver-com-spec{data-element=tec_VehMot_VehSpd_kph, filter=data-filter-type=ALWAYS, init-value=0}, required-interface=IF_VehMot_VehSpd_kph
    behavior CtAp_TrsmProtd_InternalBehavior
      timing event TMT_R_TrsmProtd_Cyclic_10ms: start-on-event=R_TrsmProtd_Cyclic_10ms, period=0.01
      init event CtAp_TrsmProtd_InitEvent: start-on-event=R_TrsmProtd_Init
      runnable R_TrsmProtd_Cyclic_10ms
        data-receive-point-by-arguments:
          9 x access:
            REC_RTE_R_ComM_IBSRLMovgDir_Enum_tec_ComM_IBSRLMovgDir_Enum: accessed-variable=RTE_R_ComM_IBSRLMovgDir_Enum.tec_ComM_IBSRLMovgDir_Enum
            REC_RTE_R_ComM_IBSRLSpd_kph_tec_ComM_IBSRLSpd_kph: accessed-variable=RTE_R_ComM_IBSRLSpd_kph.tec_ComM_IBSRLSpd_kph
            REC_RTE_R_Comm_IBSRLSpdVld_Flg_tec_ComM_IBSRLSpdVld_Flg: accessed-variable=RTE_R_ComM_IBSRLSpdVld_Flg.tec_ComM_IBSRLSpdVld_Flg
            REC_RTE_R_ComM_IBSRRMovgDir_Enum_tec_ComM_IBSRRMovgDir_Enum: accessed-variable=RTE_R_ComM_IBSRRMovgDir_Enum.tec_ComM_IBSRRMovgDir_Enum
            REC_RTE_R_Comm_IBSRrSpd_kph_tec_ComM_IBSRRSpd_kph: accessed-variable=RTE_R_ComM_IBSRrSpd_kph.tec_ComM_IBSRRSpd_kph
            REC_RTE_R_Comm_IBSRRSpdVld_Flg_tec_ComM_IBSRRSpdVld_Flg: accessed-variable=RTE_R_ComM_IBSRRSpdVld_Flg.tec_ComM_IBSRRSpdVld_Flg
            REC_RTE_R_ComM_MotActSpd_rpm_tec_ComM_MotActSpd_rpm: accessed-variable=RTE_R_ComM_MotActSpd_rpm.tec_ComM_MotActSpd_rpm
            REC_RTE_R_GearMgmt_ActGear_Enum_tec_GearMgmt_ActGear_Enum: accessed-variable=RTE_R_GearMgmt_ActGear_Enum.tec_GearMgmt_ActGear_Enum
            REC_RTE_R_VehMot_VehSpd_kph_tec_VehMot_VehSpd_kph: accessed-variable=RTE_R_VehMot_VehSpd_kph.tec_VehMot_VehSpd_kph
        data-send-points:
          access SEND_RTE_P_TorqPahMgmt_TramProtdLimMaxTq_Nm_tec_TorqPahMgmt_TramProtdLmtMaxTq_Nm: accessed-variable=RTE_P_TorqPahMgmt_TramProtdLimMaxTq_Nm.tec_TorqPahMgmt_TramProtdLmtMaxTq_Nm
          access SEND_RTE_P_TorqPahMgmt_TramProtdLimMinTq_Nm_tec_TorqPahMgmt_TramProtdLmtMinTq_Nm: accessed-variable=RTE_P_TorqPahMgmt_TramProtdLimMinTq_Nm.tec_TorqPahMgmt_TramProtdLmtMinTq_Nm
      runnable R_TrsmProtd_Init
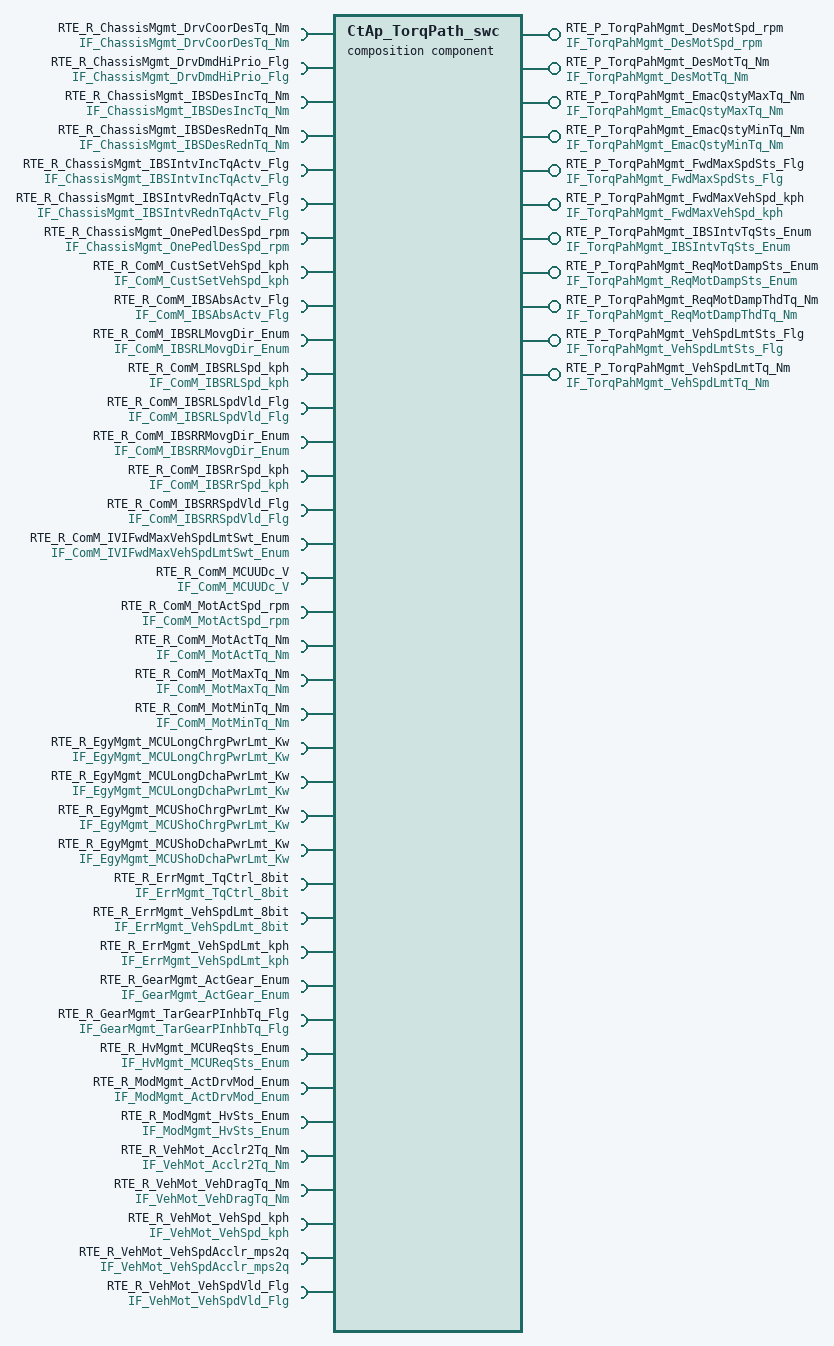
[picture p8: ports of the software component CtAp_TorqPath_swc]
  composition sw component type CtAp_TorqPath_swc
    11 x provide port:
      RTE_P_TorqPahMgmt_DesMotSpd_rpm: nonqueued-sender-com-spec{data-element=tec_TorqPahMgmt_DesMotSpd_rpm, init-value=0}, provided-interface=IF_TorqPahMgmt_DesMotSpd_rpm
      RTE_P_TorqPahMgmt_DesMotTq_Nm: nonqueued-sender-com-spec{data-element=tec_TorqPahMgmt_DesMotTq_Nm, init-value=0}, provided-interface=IF_TorqPahMgmt_DesMotTq_Nm
      RTE_P_TorqPahMgmt_EmacQstyMaxTq_Nm: nonqueued-sender-com-spec{data-element=tec_TorqPahMgmt_EmacQstyMaxTq_Nm, init-value=0}, provided-interface=IF_TorqPahMgmt_EmacQstyMaxTq_Nm
      RTE_P_TorqPahMgmt_EmacQstyMinTq_Nm: nonqueued-sender-com-spec{data-element=tec_TorqPahMgmt_EmacQstyMinTq_Nm, init-value=0}, provided-interface=IF_TorqPahMgmt_EmacQstyMinTq_Nm
      RTE_P_TorqPahMgmt_FwdMaxSpdSts_Flg: nonqueued-sender-com-spec{data-element=tec_TorqPahMgmt_FwdMaxSpdSts_Flg, init-value=0}, provided-interface=IF_TorqPahMgmt_FwdMaxSpdSts_Flg
      RTE_P_TorqPahMgmt_FwdMaxVehSpd_kph: nonqueued-sender-com-spec{data-element=tec_TorqPahMgmt_FwdMaxVehSpd_kph, init-value=0}, provided-interface=IF_TorqPahMgmt_FwdMaxVehSpd_kph
      RTE_P_TorqPahMgmt_IBSIntvTqSts_Enum: nonqueued-sender-com-spec{data-element=tec_TorqPahMgmt_IBSIntvTqSts_Enum, init-value=0}, provided-interface=IF_TorqPahMgmt_IBSIntvTqSts_Enum
      RTE_P_TorqPahMgmt_ReqMotDampSts_Enum: nonqueued-sender-com-spec{data-element=tec_TorqPahMgmt_ReqMotDampSts_Enum, init-value=0}, provided-interface=IF_TorqPahMgmt_ReqMotDampSts_Enum
      RTE_P_TorqPahMgmt_ReqMotDampThdTq_Nm: nonqueued-sender-com-spec{data-element=tec_TorqPahMgmt_ReqMotDampThdTq_Nm, init-value=0}, provided-interface=IF_TorqPahMgmt_ReqMotDampThdTq_Nm
      RTE_P_TorqPahMgmt_VehSpdLmtSts_Flg: nonqueued-sender-com-spec{data-element=tec_TorqPahMgmt_VehSpdLmtSts_Flg, init-value=0}, provided-interface=IF_TorqPahMgmt_VehSpdLmtSts_Flg
      RTE_P_TorqPahMgmt_VehSpdLmtTq_Nm: nonqueued-sender-com-spec{data-element=tec_TorqPahMgmt_VehSpdLmtTq_Nm, init-value=0}, provided-interface=IF_TorqPahMgmt_VehSpdLmtTq_Nm
    38 x require port:
      RTE_R_ChassisMgmt_DrvCoorDesTq_Nm: nonqueued-receiver-com-spec{data-element=tec_ChassisMgmt_DrvCoorDesTq_Nm, filter=data-filter-type=ALWAYS}, required-interface=IF_ChassisMgmt_DrvCoorDesTq_Nm
      RTE_R_ChassisMgmt_DrvDmdHiPrio_Flg: nonqueued-receiver-com-spec{data-element=tec_ChassisMgmt_DrvDmdHiPrio_Flg, filter=data-filter-type=ALWAYS}, required-interface=IF_ChassisMgmt_DrvDmdHiPrio_Flg
      RTE_R_ChassisMgmt_IBSDesIncTq_Nm: nonqueued-receiver-com-spec{data-element=tec_ChassisMgmt_IBSDesIncTq_Nm, filter=data-filter-type=ALWAYS}, required-interface=IF_ChassisMgmt_IBSDesIncTq_Nm
      RTE_R_ChassisMgmt_IBSDesRednTq_Nm: nonqueued-receiver-com-spec{data-element=tec_ChassisMgmt_IBSDesRednTq_Nm, filter=data-filter-type=ALWAYS}, required-interface=IF_ChassisMgmt_IBSDesRednTq_Nm
      RTE_R_ChassisMgmt_IBSIntvIncTqActv_Flg: nonqueued-receiver-com-spec{data-element=tec_ChassisMgmt_IBSIntvIncTqActv_Flg, filter=data-filter-type=ALWAYS}, required-interface=IF_ChassisMgmt_IBSIntvIncTqActv_Flg
      RTE_R_ChassisMgmt_IBSIntvRednTqActv_Flg: nonqueued-receiver-com-spec{data-element=tec_ChassisMgmt_IBSIntvRednTqActv_Flg, filter=data-filter-type=ALWAYS}, required-interface=IF_ChassisMgmt_IBSIntvRednTqActv_Flg
      RTE_R_ChassisMgmt_OnePedlDesSpd_rpm: nonqueued-receiver-com-spec{data-element=tec_ChassisMgmt_OnePedlDesSpd_rpm, filter=data-filter-type=ALWAYS}, required-interface=IF_ChassisMgmt_OnePedlDesSpd_rpm
      RTE_R_ComM_CustSetVehSpd_kph: nonqueued-receiver-com-spec{data-element=tec_ComM_IVISetFwdVehSpd_kph, filter=data-filter-type=ALWAYS}, required-interface=IF_ComM_CustSetVehSpd_kph
      RTE_R_ComM_IBSAbsActv_Flg: nonqueued-receiver-com-spec{data-element=tec_ComM_IBSAbsActv_Flg, filter=data-filter-type=ALWAYS}, required-interface=IF_ComM_IBSAbsActv_Flg
      RTE_R_ComM_IBSRLMovgDir_Enum: nonqueued-receiver-com-spec{data-element=tec_ComM_IBSRLMovgDir_Enum, filter=data-filter-type=ALWAYS}, required-interface=IF_ComM_IBSRLMovgDir_Enum
      RTE_R_ComM_IBSRLSpd_kph: nonqueued-receiver-com-spec{data-element=tec_ComM_IBSRLSpd_kph, filter=data-filter-type=ALWAYS}, required-interface=IF_ComM_IBSRLSpd_kph
      RTE_R_ComM_IBSRLSpdVld_Flg: nonqueued-receiver-com-spec{data-element=tec_ComM_IBSRLSpdVld_Flg, filter=data-filter-type=ALWAYS}, required-interface=IF_ComM_IBSRLSpdVld_Flg
      RTE_R_ComM_IBSRRMovgDir_Enum: nonqueued-receiver-com-spec{data-element=tec_ComM_IBSRRMovgDir_Enum, filter=data-filter-type=ALWAYS}, required-interface=IF_ComM_IBSRRMovgDir_Enum
      RTE_R_ComM_IBSRrSpd_kph: nonqueued-receiver-com-spec{data-element=tec_ComM_IBSRRSpd_kph, filter=data-filter-type=ALWAYS}, required-interface=IF_ComM_IBSRrSpd_kph
      RTE_R_ComM_IBSRRSpdVld_Flg: nonqueued-receiver-com-spec{data-element=tec_ComM_IBSRRSpdVld_Flg, filter=data-filter-type=ALWAYS}, required-interface=IF_ComM_IBSRRSpdVld_Flg
      RTE_R_ComM_IVIFwdMaxVehSpdLmtSwt_Enum: nonqueued-receiver-com-spec{data-element=tec_ComM_IVIFwdMaxVehSpdLmtSwt_Enum, filter=data-filter-type=ALWAYS}, required-interface=IF_ComM_IVIFwdMaxVehSpdLmtSwt_Enum
      RTE_R_ComM_MCUUDc_V: nonqueued-receiver-com-spec{data-element=tec_ComM_MCUUDc_V, filter=data-filter-type=ALWAYS}, required-interface=IF_ComM_MCUUDc_V
      RTE_R_ComM_MotActSpd_rpm: nonqueued-receiver-com-spec{data-element=tec_ComM_MotActSpd_rpm, filter=data-filter-type=ALWAYS}, required-interface=IF_ComM_MotActSpd_rpm
      RTE_R_ComM_MotActTq_Nm: nonqueued-receiver-com-spec{data-element=tec_ComM_MotActTq_Nm, filter=data-filter-type=ALWAYS}, required-interface=IF_ComM_MotActTq_Nm
      RTE_R_ComM_MotMaxTq_Nm: nonqueued-receiver-com-spec{data-element=tec_ComM_MotMaxTq_Nm, filter=data-filter-type=ALWAYS}, required-interface=IF_ComM_MotMaxTq_Nm
      RTE_R_ComM_MotMinTq_Nm: nonqueued-receiver-com-spec{data-element=tec_ComM_MotMinTq_Nm, filter=data-filter-type=ALWAYS}, required-interface=IF_ComM_MotMinTq_Nm
      RTE_R_EgyMgmt_MCULongChrgPwrLmt_Kw: nonqueued-receiver-com-spec{data-element=tec_EgyMgmt_MCULongChrgPwrLmt_Kw, filter=data-filter-type=ALWAYS}, required-interface=IF_EgyMgmt_MCULongChrgPwrLmt_Kw
      RTE_R_EgyMgmt_MCULongDchaPwrLmt_Kw: nonqueued-receiver-com-spec{data-element=tec_EgyMgmt_MCULongDchaPwrLmt_Kw, filter=data-filter-type=ALWAYS}, required-interface=IF_EgyMgmt_MCULongDchaPwrLmt_Kw
      RTE_R_EgyMgmt_MCUShoChrgPwrLmt_Kw: nonqueued-receiver-com-spec{data-element=tec_EgyMgmt_MCUShoChrgPwrLmt_Kw, filter=data-filter-type=ALWAYS}, required-interface=IF_EgyMgmt_MCUShoChrgPwrLmt_Kw
      RTE_R_EgyMgmt_MCUShoDchaPwrLmt_Kw: nonqueued-receiver-com-spec{data-element=tec_EgyMgmt_MCUShoDchaPwrLmt_Kw, filter=data-filter-type=ALWAYS}, required-interface=IF_EgyMgmt_MCUShoDchaPwrLmt_Kw
      RTE_R_ErrMgmt_TqCtrl_8bit: nonqueued-receiver-com-spec{data-element=tec_ErrMgmt_TqCtrl_8bit, filter=data-filter-type=ALWAYS}, required-interface=IF_ErrMgmt_TqCtrl_8bit
      RTE_R_ErrMgmt_VehSpdLmt_8bit: nonqueued-receiver-com-spec{data-element=tec_ErrMgmt_VehSpdLmt_8bit, filter=data-filter-type=ALWAYS}, required-interface=IF_ErrMgmt_VehSpdLmt_8bit
      RTE_R_ErrMgmt_VehSpdLmt_kph: nonqueued-receiver-com-spec{data-element=tec_ErrMgmt_VehSpdLmt_kph, filter=data-filter-type=ALWAYS}, required-interface=IF_ErrMgmt_VehSpdLmt_kph
      RTE_R_GearMgmt_ActGear_Enum: nonqueued-receiver-com-spec{data-element=tec_GearMgmt_ActGear_Enum, filter=data-filter-type=ALWAYS}, required-interface=IF_GearMgmt_ActGear_Enum
      RTE_R_GearMgmt_TarGearPInhbTq_Flg: nonqueued-receiver-com-spec{data-element=tec_GearMgmt_TarGearPInhbTq_Flg, filter=data-filter-type=ALWAYS}, required-interface=IF_GearMgmt_TarGearPInhbTq_Flg
      RTE_R_HvMgmt_MCUReqSts_Enum: nonqueued-receiver-com-spec{data-element=tec_HvMgmt_MCUReqSts_Enum, filter=data-filter-type=ALWAYS}, required-interface=IF_HvMgmt_MCUReqSts_Enum
      RTE_R_ModMgmt_ActDrvMod_Enum: nonqueued-receiver-com-spec{data-element=tec_ModMgmt_ActDrvMod_Enum, filter=data-filter-type=ALWAYS}, required-interface=IF_ModMgmt_ActDrvMod_Enum
      RTE_R_ModMgmt_HvSts_Enum: nonqueued-receiver-com-spec{data-element=tec_ModMgmt_HvSts_Enum, filter=data-filter-type=ALWAYS}, required-interface=IF_ModMgmt_HvSts_Enum
      RTE_R_VehMot_Acclr2Tq_Nm: nonqueued-receiver-com-spec{data-element=tec_VehMot_Acclr2Tq_Nm, filter=data-filter-type=ALWAYS}, required-interface=IF_VehMot_Acclr2Tq_Nm
      RTE_R_VehMot_VehDragTq_Nm: nonqueued-receiver-com-spec{data-element=tec_VehMot_VehDragTq_Nm, filter=data-filter-type=ALWAYS}, required-interface=IF_VehMot_VehDragTq_Nm
      RTE_R_VehMot_VehSpd_kph: nonqueued-receiver-com-spec{data-element=tec_VehMot_VehSpd_kph, filter=data-filter-type=ALWAYS}, required-interface=IF_VehMot_VehSpd_kph
      RTE_R_VehMot_VehSpdAcclr_mps2q: nonqueued-receiver-com-spec{data-element=tec_VehMot_VehSpdAcclr_mps2q, filter=data-filter-type=ALWAYS}, required-interface=IF_VehMot_VehSpdAcclr_mps2q
      RTE_R_VehMot_VehSpdVld_Flg: nonqueued-receiver-com-spec{data-element=tec_VehMot_VehSpdVld_Flg, filter=data-filter-type=ALWAYS}, required-interface=IF_VehMot_VehSpdVld_Flg
    8 x component:
      CtAp_SpdLmt: type=CtAp_SpdLmt
      CtAp_TorqCoor: type=CtAp_TorqCoor
      CtAp_TorqCrossZr: type=CtAp_TorqCrossZr
      CtAp_TorqDamp: type=CtAp_TorqDamp
      CtAp_TorqFil: type=CtAp_TorqFil
      CtAp_TorqLmt: type=CtAp_TorqLmt
      CtAp_TorqModMap: type=CtAp_TorqModMap
      CtAp_TrsmProtd: type=CtAp_TrsmProtd
    connect CtAp_TorqCoor.RTE_P_TorqPahMgmt_DesCoorTq_Nm -> CtAp_TorqModMap.RTE_R_TorqPahMgmt_DesCoorTq_Nm
    connect CtAp_TorqCrossZr.RTE_P_TorqPahMgmt_DesFildTq_Nm -> CtAp_TorqCoor.RTE_R_TorqPahMgmt_DesFildTq_Nm
    connect CtAp_TorqFil.RTE_P_TorqPahMgmt_DesLpFildTq_Nm -> CtAp_TorqCrossZr.RTE_R_TorqPahMgmt_DesLpFildTq_Nm
    connect CtAp_TorqLmt.RTE_P_TorqPahMgmt_EmacQstyMaxTq_Nm -> CtAp_SpdLmt.RTE_R_TorqPahMgmt_EmacQstyMaxTq_Nm
    connect CtAp_TorqLmt.RTE_P_TorqPahMgmt_EmacQstyMinTq_Nm -> CtAp_SpdLmt.RTE_R_TorqPahMgmt_EmacQstyMinTq_Nm
    connect CtAp_TorqLmt.RTE_P_TorqPahMgmt_EmacDynMaxTq_Nm -> CtAp_TorqCoor.RTE_R_TorqPahMgmt_EmacDynMaxTq_Nm
    connect CtAp_TorqLmt.RTE_P_TorqPahMgmt_EmacDynMinTq_Nm -> CtAp_TorqCoor.RTE_R_TorqPahMgmt_EmacDynMinTq_Nm
    connect CtAp_TorqLmt.RTE_P_TorqPahMgmt_EmacQstyMaxTq_Nm -> CtAp_TorqDamp.RTE_R_TorqPahMgmt_EmacQstyMaxTq_Nm
    connect CtAp_TorqLmt.RTE_P_TorqPahMgmt_EmacQstyMinTq_Nm -> CtAp_TorqDamp.RTE_R_TorqPahMgmt_EmacQstyMinTq_Nm
    connect CtAp_TorqLmt.RTE_P_TorqPahMgmt_EmacQstyMaxTq_Nm -> CtAp_TorqFil.RTE_R_TorqPahMgmt_EmacQstyMaxTq_Nm
    connect CtAp_TorqLmt.RTE_P_TorqPahMgmt_EmacQstyMinTq_Nm -> CtAp_TorqFil.RTE_R_TorqPahMgmt_EmacQstyMinTq_Nm
    connect CtAp_TrsmProtd.RTE_P_TorqPahMgmt_TramProtdLimMaxTq_Nm -> CtAp_TorqModMap.RTE_R_TorqPahMgmt_TramProtdLmtMaxTq_Nm
    connect CtAp_TrsmProtd.RTE_P_TorqPahMgmt_TramProtdLimMinTq_Nm -> CtAp_TorqModMap.RTE_R_TorqPahMgmt_TramProtdLmtMinTq_Nm
    delegate CtAp_TorqModMap.RTE_P_TorqPahMgmt_DesMotSpd_rpm <-> outer port CtAp_TorqPath_swc/RTE_P_TorqPahMgmt_DesMotSpd_rpm
    delegate CtAp_TorqModMap.RTE_P_TorqPahMgmt_DesMotTq_Nm <-> outer port CtAp_TorqPath_swc/RTE_P_TorqPahMgmt_DesMotTq_Nm
    delegate CtAp_TorqLmt.RTE_P_TorqPahMgmt_EmacQstyMaxTq_Nm <-> outer port CtAp_TorqPath_swc/RTE_P_TorqPahMgmt_EmacQstyMaxTq_Nm
    delegate CtAp_TorqLmt.RTE_P_TorqPahMgmt_EmacQstyMinTq_Nm <-> outer port CtAp_TorqPath_swc/RTE_P_TorqPahMgmt_EmacQstyMinTq_Nm
    delegate CtAp_SpdLmt.RTE_P_TorqPahMgmt_FwdMaxSpdSts_Flg <-> outer port CtAp_TorqPath_swc/RTE_P_TorqPahMgmt_FwdMaxSpdSts_Flg
    delegate CtAp_SpdLmt.RTE_P_TorqPahMgmt_FwdMaxVehSpd_kph <-> outer port CtAp_TorqPath_swc/RTE_P_TorqPahMgmt_FwdMaxVehSpd_kph
    delegate CtAp_TorqCoor.RTE_P_TorqPahMgmt_IBSIntvTqSts_Enum <-> outer port CtAp_TorqPath_swc/RTE_P_TorqPahMgmt_IBSIntvTqSts_Enum
    delegate CtAp_TorqDamp.RTE_P_TorqPahMgmt_ReqMotDampSts_Enum <-> outer port CtAp_TorqPath_swc/RTE_P_TorqPahMgmt_ReqMotDampSts_Enum
    delegate CtAp_TorqDamp.RTE_P_TorqPahMgmt_ReqMotDampThdTq_Nm <-> outer port CtAp_TorqPath_swc/RTE_P_TorqPahMgmt_ReqMotDampThdTq_Nm
    delegate CtAp_SpdLmt.RTE_P_TorqPahMgmt_VehSpdLmtSts_Flg <-> outer port CtAp_TorqPath_swc/RTE_P_TorqPahMgmt_VehSpdLmtSts_Flg
    delegate CtAp_SpdLmt.RTE_P_TorqPahMgmt_VehSpdLmtTq_Nm <-> outer port CtAp_TorqPath_swc/RTE_P_TorqPahMgmt_VehSpdLmtTq_Nm
    delegate CtAp_TorqFil.RTE_R_ChassisMgmt_DrvCoorDesTq_Nm <-> outer port CtAp_TorqPath_swc/RTE_R_ChassisMgmt_DrvCoorDesTq_Nm
    delegate CtAp_TorqCrossZr.RTE_R_ChassisMgmt_DrvDmdHiPrio_Flg <-> outer port CtAp_TorqPath_swc/RTE_R_ChassisMgmt_DrvDmdHiPrio_Flg
    delegate CtAp_TorqFil.RTE_R_ChassisMgmt_DrvDmdHiPrio_Flg <-> outer port CtAp_TorqPath_swc/RTE_R_ChassisMgmt_DrvDmdHiPrio_Flg
    delegate CtAp_TorqCoor.RTE_R_ChassisMgmt_IBSDesIncTq_Nm <-> outer port CtAp_TorqPath_swc/RTE_R_ChassisMgmt_IBSDesIncTq_Nm
    delegate CtAp_TorqCoor.RTE_R_ChassisMgmt_IBSDesRednTq_Nm <-> outer port CtAp_TorqPath_swc/RTE_R_ChassisMgmt_IBSDesRednTq_Nm
    delegate CtAp_TorqCoor.RTE_R_ChassisMgmt_IBSIntvIncTqActv_Flg <-> outer port CtAp_TorqPath_swc/RTE_R_ChassisMgmt_IBSIntvIncTqActv_Flg
    delegate CtAp_TorqDamp.RTE_R_ChassisMgmt_IBSIntvIncTqActv_Flg <-> outer port CtAp_TorqPath_swc/RTE_R_ChassisMgmt_IBSIntvIncTqActv_Flg
    delegate CtAp_TorqCoor.RTE_R_ChassisMgmt_IBSIntvRednTqActv_Flg <-> outer port CtAp_TorqPath_swc/RTE_R_ChassisMgmt_IBSIntvRednTqActv_Flg
    delegate CtAp_TorqDamp.RTE_R_ChassisMgmt_IBSIntvRednTqActv_Flg <-> outer port CtAp_TorqPath_swc/RTE_R_ChassisMgmt_IBSIntvRednTqActv_Flg
    delegate CtAp_TorqModMap.RTE_R_ChassisMgmt_OnePedlDesSpd_rpm <-> outer port CtAp_TorqPath_swc/RTE_R_ChassisMgmt_OnePedlDesSpd_rpm
    delegate CtAp_SpdLmt.RTE_R_ComM_CustSetVehSpd_kph <-> outer port CtAp_TorqPath_swc/RTE_R_ComM_CustSetVehSpd_kph
    delegate CtAp_TorqDamp.RTE_R_ComM_IBSAbsActv_Flg <-> outer port CtAp_TorqPath_swc/RTE_R_ComM_IBSAbsActv_Flg
    delegate CtAp_TrsmProtd.RTE_R_ComM_IBSRLMovgDir_Enum <-> outer port CtAp_TorqPath_swc/RTE_R_ComM_IBSRLMovgDir_Enum
    delegate CtAp_TrsmProtd.RTE_R_ComM_IBSRLSpd_kph <-> outer port CtAp_TorqPath_swc/RTE_R_ComM_IBSRLSpd_kph
    delegate CtAp_TrsmProtd.RTE_R_ComM_IBSRLSpdVld_Flg <-> outer port CtAp_TorqPath_swc/RTE_R_ComM_IBSRLSpdVld_Flg
    delegate CtAp_TrsmProtd.RTE_R_ComM_IBSRRMovgDir_Enum <-> outer port CtAp_TorqPath_swc/RTE_R_ComM_IBSRRMovgDir_Enum
    delegate CtAp_TrsmProtd.RTE_R_ComM_IBSRrSpd_kph <-> outer port CtAp_TorqPath_swc/RTE_R_ComM_IBSRrSpd_kph
    delegate CtAp_TorqDamp.RTE_R_ComM_IBSRRSpdVld_Flg <-> outer port CtAp_TorqPath_swc/RTE_R_ComM_IBSRRSpdVld_Flg
    delegate CtAp_TrsmProtd.RTE_R_ComM_IBSRRSpdVld_Flg <-> outer port CtAp_TorqPath_swc/RTE_R_ComM_IBSRRSpdVld_Flg
    delegate CtAp_SpdLmt.RTE_R_ComM_IVIFwdMaxVehSpdLmtSwt_Enum <-> outer port CtAp_TorqPath_swc/RTE_R_ComM_IVIFwdMaxVehSpdLmtSwt_Enum
    delegate CtAp_TorqLmt.RTE_R_ComM_MCUUDc_V <-> outer port CtAp_TorqPath_swc/RTE_R_ComM_MCUUDc_V
    delegate CtAp_TorqLmt.RTE_R_ComM_MotActSpd_rpm <-> outer port CtAp_TorqPath_swc/RTE_R_ComM_MotActSpd_rpm
    delegate CtAp_TrsmProtd.RTE_R_ComM_MotActSpd_rpm <-> outer port CtAp_TorqPath_swc/RTE_R_ComM_MotActSpd_rpm
    delegate CtAp_TorqModMap.RTE_R_ComM_MotActTq_Nm <-> outer port CtAp_TorqPath_swc/RTE_R_ComM_MotActTq_Nm
    delegate CtAp_TorqLmt.RTE_R_ComM_MotMaxTq_Nm <-> outer port CtAp_TorqPath_swc/RTE_R_ComM_MotMaxTq_Nm
    delegate CtAp_TorqLmt.RTE_R_ComM_MotMinTq_Nm <-> outer port CtAp_TorqPath_swc/RTE_R_ComM_MotMinTq_Nm
    delegate CtAp_TorqLmt.RTE_R_EgyMgmt_MCULongChrgPwrLmt_Kw <-> outer port CtAp_TorqPath_swc/RTE_R_EgyMgmt_MCULongChrgPwrLmt_Kw
    delegate CtAp_TorqLmt.RTE_R_EgyMgmt_MCULongDchaPwrLmt_Kw <-> outer port CtAp_TorqPath_swc/RTE_R_EgyMgmt_MCULongDchaPwrLmt_Kw
    delegate CtAp_TorqLmt.RTE_R_EgyMgmt_MCUShoChrgPwrLmt_Kw <-> outer port CtAp_TorqPath_swc/RTE_R_EgyMgmt_MCUShoChrgPwrLmt_Kw
    delegate CtAp_TorqLmt.RTE_R_EgyMgmt_MCUShoDchaPwrLmt_Kw <-> outer port CtAp_TorqPath_swc/RTE_R_EgyMgmt_MCUShoDchaPwrLmt_Kw
    delegate CtAp_TorqLmt.RTE_R_ErrMgmt_TqCtrl_8bit <-> outer port CtAp_TorqPath_swc/RTE_R_ErrMgmt_TqCtrl_8bit
    delegate CtAp_SpdLmt.RTE_R_ErrMgmt_VehSpdLmt_8bit <-> outer port CtAp_TorqPath_swc/RTE_R_ErrMgmt_VehSpdLmt_8bit
    delegate CtAp_SpdLmt.RTE_R_ErrMgmt_VehSpdLmt_kph <-> outer port CtAp_TorqPath_swc/RTE_R_ErrMgmt_VehSpdLmt_kph
    delegate CtAp_SpdLmt.RTE_R_GearMgmt_ActGear_Enum <-> outer port CtAp_TorqPath_swc/RTE_R_GearMgmt_ActGear_Enum
    delegate CtAp_TorqDamp.RTE_R_GearMgmt_ActGear_Enum <-> outer port CtAp_TorqPath_swc/RTE_R_GearMgmt_ActGear_Enum
    delegate CtAp_TrsmProtd.RTE_R_GearMgmt_ActGear_Enum <-> outer port CtAp_TorqPath_swc/RTE_R_GearMgmt_ActGear_Enum
    delegate CtAp_TorqModMap.RTE_R_GearMgmt_TarGearPInhbTq_Flg <-> outer port CtAp_TorqPath_swc/RTE_R_GearMgmt_TarGearPInhbTq_Flg
    delegate CtAp_TorqModMap.RTE_R_HvMgmt_MCUReqSts_Enum <-> outer port CtAp_TorqPath_swc/RTE_R_HvMgmt_MCUReqSts_Enum
    delegate CtAp_TorqCrossZr.RTE_R_ModMgmt_ActDrvMod_Enum <-> outer port CtAp_TorqPath_swc/RTE_R_ModMgmt_ActDrvMod_Enum
    delegate CtAp_SpdLmt.RTE_R_ModMgmt_HvSts_Enum <-> outer port CtAp_TorqPath_swc/RTE_R_ModMgmt_HvSts_Enum
    delegate CtAp_TorqCoor.RTE_R_ModMgmt_HvSts_Enum <-> outer port CtAp_TorqPath_swc/RTE_R_ModMgmt_HvSts_Enum
    delegate CtAp_TorqDamp.RTE_R_ModMgmt_HvSts_Enum <-> outer port CtAp_TorqPath_swc/RTE_R_ModMgmt_HvSts_Enum
    delegate CtAp_SpdLmt.RTE_R_VehMot_Acclr2Tq_Nm <-> outer port CtAp_TorqPath_swc/RTE_R_VehMot_Acclr2Tq_Nm
    delegate CtAp_SpdLmt.RTE_R_VehMot_VehDragTq_Nm <-> outer port CtAp_TorqPath_swc/RTE_R_VehMot_VehDragTq_Nm
    delegate CtAp_TrsmProtd.RTE_R_VehMot_VehSpd_kph <-> outer port CtAp_TorqPath_swc/RTE_R_VehMot_VehSpd_kph
    delegate CtAp_SpdLmt.RTE_R_VehMot_VehSpd_kph <-> outer port CtAp_TorqPath_swc/RTE_R_VehMot_VehSpd_kph
    delegate CtAp_TorqCoor.RTE_R_VehMot_VehSpd_kph <-> outer port CtAp_TorqPath_swc/RTE_R_VehMot_VehSpd_kph
    delegate CtAp_TorqCrossZr.RTE_R_VehMot_VehSpd_kph <-> outer port CtAp_TorqPath_swc/RTE_R_VehMot_VehSpd_kph
    delegate CtAp_SpdLmt.RTE_R_VehMot_VehSpdAcclr_mps2q <-> outer port CtAp_TorqPath_swc/RTE_R_VehMot_VehSpdAcclr_mps2q
    delegate CtAp_TorqCoor.RTE_R_VehMot_VehSpdVld_Flg <-> outer port CtAp_TorqPath_swc/RTE_R_VehMot_VehSpdVld_Flg
    delegate CtAp_SpdLmt.RTE_R_VehMot_VehSpdVld_Flg <-> outer port CtAp_TorqPath_swc/RTE_R_VehMot_VehSpdVld_Flg
  8 x swc implementation:
    CtAp_SpdLmt_Implementation: behavior=CtAp_SpdLmt_InternalBehavior
      code-descriptors:
        code Default: artifact-descriptors=autosar-engineering-object={short-label=Default, category=SWOBJ}
    CtAp_TorqCoor_Implementation: behavior=CtAp_TorqCoor_InternalBehavior
      code-descriptors:
        code Default: artifact-descriptors=autosar-engineering-object={short-label=Default, category=SWOBJ}
    CtAp_TorqCrossZr_Implementation: behavior=CtAp_TorqCrossZr_InternalBehavior
      code-descriptors:
        code Default: artifact-descriptors=autosar-engineering-object={short-label=Default, category=SWOBJ}
    CtAp_TorqDamp_Implementation: behavior=CtAp_TorqDamp_InternalBehavior
      code-descriptors:
        code Default: artifact-descriptors=autosar-engineering-object={short-label=Default, category=SWOBJ}
    CtAp_TorqFil_Implementation: behavior=CtAp_TorqFil_InternalBehavior
      code-descriptors:
        code Default: artifact-descriptors=autosar-engineering-object={short-label=Default, category=SWOBJ}
    CtAp_TorqLmt_Implementation: behavior=CtAp_TorqLmt_InternalBehavior
      code-descriptors:
        code Default: artifact-descriptors=autosar-engineering-object={short-label=Default, category=SWOBJ}
    CtAp_TorqModMap_Implementation: behavior=CtAp_TorqModMap_InternalBehavior
      code-descriptors:
        code Default: artifact-descriptors=autosar-engineering-object={short-label=Default, category=SWOBJ}
    CtAp_TrsmProtd_Implementation: behavior=CtAp_TrsmProtd_InternalBehavior
      code-descriptors:
        code Default: artifact-descriptors=autosar-engineering-object={short-label=Default, category=SWOBJ}
package /PortInterfaces
  58 x sender receiver interface:
    IF_ChassisMgmt_DrvCoorDesTq_Nm: invalidation-policy{data-element=tec_ChassisMgmt_DrvCoorDesTq_Nm, handle-invalid=DONT-INVALIDATE}
      data tec_ChassisMgmt_DrvCoorDesTq_Nm: type=float32
    IF_ChassisMgmt_DrvDmdHiPrio_Flg: invalidation-policy{data-element=tec_ChassisMgmt_DrvDmdHiPrio_Flg, handle-invalid=DONT-INVALIDATE}
      data tec_ChassisMgmt_DrvDmdHiPrio_Flg: type=boolean
    IF_ChassisMgmt_IBSDesIncTq_Nm: invalidation-policy{data-element=tec_ChassisMgmt_IBSDesIncTq_Nm, handle-invalid=DONT-INVALIDATE}
      data tec_ChassisMgmt_IBSDesIncTq_Nm: type=float32
    IF_ChassisMgmt_IBSDesRednTq_Nm: invalidation-policy{data-element=tec_ChassisMgmt_IBSDesRednTq_Nm, handle-invalid=DONT-INVALIDATE}
      data tec_ChassisMgmt_IBSDesRednTq_Nm: type=float32
    IF_ChassisMgmt_IBSIntvIncTqActv_Flg: invalidation-policy{data-element=tec_ChassisMgmt_IBSIntvIncTqActv_Flg, handle-invalid=DONT-INVALIDATE}
      data tec_ChassisMgmt_IBSIntvIncTqActv_Flg: type=boolean
    IF_ChassisMgmt_IBSIntvRednTqActv_Flg: invalidation-policy{data-element=tec_ChassisMgmt_IBSIntvRednTqActv_Flg, handle-invalid=DONT-INVALIDATE}
      data tec_ChassisMgmt_IBSIntvRednTqActv_Flg: type=boolean
    IF_ChassisMgmt_OnePedlDesSpd_rpm: invalidation-policy{data-element=tec_ChassisMgmt_OnePedlDesSpd_rpm, handle-invalid=DONT-INVALIDATE}
      data tec_ChassisMgmt_OnePedlDesSpd_rpm: type=float32
    IF_ComM_CustSetVehSpd_kph: invalidation-policy{data-element=tec_ComM_IVISetFwdVehSpd_kph, handle-invalid=DONT-INVALIDATE}
      data tec_ComM_IVISetFwdVehSpd_kph: type=float32
    IF_ComM_IBSAbsActv_Flg: invalidation-policy{data-element=tec_ComM_IBSAbsActv_Flg, handle-invalid=DONT-INVALIDATE}
      data tec_ComM_IBSAbsActv_Flg: type=boolean
    IF_ComM_IBSRLMovgDir_Enum: invalidation-policy{data-element=tec_ComM_IBSRLMovgDir_Enum, handle-invalid=DONT-INVALIDATE}
      data tec_ComM_IBSRLMovgDir_Enum: type=uint8
    IF_ComM_IBSRLSpd_kph: invalidation-policy{data-element=tec_ComM_IBSRLSpd_kph, handle-invalid=DONT-INVALIDATE}
      data tec_ComM_IBSRLSpd_kph: type=float32
    IF_ComM_IBSRLSpdVld_Flg: invalidation-policy{data-element=tec_ComM_IBSRLSpdVld_Flg, handle-invalid=DONT-INVALIDATE}
      data tec_ComM_IBSRLSpdVld_Flg: type=boolean
    IF_ComM_IBSRRMovgDir_Enum: invalidation-policy{data-element=tec_ComM_IBSRRMovgDir_Enum, handle-invalid=DONT-INVALIDATE}
      data tec_ComM_IBSRRMovgDir_Enum: type=uint8
    IF_ComM_IBSRrSpd_kph: invalidation-policy{data-element=tec_ComM_IBSRRSpd_kph, handle-invalid=DONT-INVALIDATE}
      data tec_ComM_IBSRRSpd_kph: type=float32
    IF_ComM_IBSRRSpdVld_Flg: invalidation-policy{data-element=tec_ComM_IBSRRSpdVld_Flg, handle-invalid=DONT-INVALIDATE}
      data tec_ComM_IBSRRSpdVld_Flg: type=boolean
    IF_ComM_IVIFwdMaxVehSpdLmtSwt_Enum: invalidation-policy{data-element=tec_ComM_IVIFwdMaxVehSpdLmtSwt_Enum, handle-invalid=DONT-INVALIDATE}
      data tec_ComM_IVIFwdMaxVehSpdLmtSwt_Enum: type=uint8
    IF_ComM_MCUUDc_V: invalidation-policy{data-element=tec_ComM_MCUUDc_V, handle-invalid=DONT-INVALIDATE}
      data tec_ComM_MCUUDc_V: type=float32
    IF_ComM_MotActSpd_rpm: invalidation-policy{data-element=tec_ComM_MotActSpd_rpm, handle-invalid=DONT-INVALIDATE}
      data tec_ComM_MotActSpd_rpm: type=sint16
    IF_ComM_MotActTq_Nm: invalidation-policy{data-element=tec_ComM_MotActTq_Nm, handle-invalid=DONT-INVALIDATE}
      data tec_ComM_MotActTq_Nm: type=float32
    IF_ComM_MotMaxTq_Nm: invalidation-policy{data-element=tec_ComM_MotMaxTq_Nm, handle-invalid=DONT-INVALIDATE}
      data tec_ComM_MotMaxTq_Nm: type=float32
    IF_ComM_MotMinTq_Nm: invalidation-policy{data-element=tec_ComM_MotMinTq_Nm, handle-invalid=DONT-INVALIDATE}
      data tec_ComM_MotMinTq_Nm: type=float32
    IF_EgyMgmt_MCULongChrgPwrLmt_Kw: invalidation-policy{data-element=tec_EgyMgmt_MCULongChrgPwrLmt_Kw, handle-invalid=DONT-INVALIDATE}
      data tec_EgyMgmt_MCULongChrgPwrLmt_Kw: type=float32
    IF_EgyMgmt_MCULongDchaPwrLmt_Kw: invalidation-policy{data-element=tec_EgyMgmt_MCULongDchaPwrLmt_Kw, handle-invalid=DONT-INVALIDATE}
      data tec_EgyMgmt_MCULongDchaPwrLmt_Kw: type=float32
    IF_EgyMgmt_MCUShoChrgPwrLmt_Kw: invalidation-policy{data-element=tec_EgyMgmt_MCUShoChrgPwrLmt_Kw, handle-invalid=DONT-INVALIDATE}
      data tec_EgyMgmt_MCUShoChrgPwrLmt_Kw: type=float32
    IF_EgyMgmt_MCUShoDchaPwrLmt_Kw: invalidation-policy{data-element=tec_EgyMgmt_MCUShoDchaPwrLmt_Kw, handle-invalid=DONT-INVALIDATE}
      data tec_EgyMgmt_MCUShoDchaPwrLmt_Kw: type=float32
    IF_ErrMgmt_TqCtrl_8bit: invalidation-policy{data-element=tec_ErrMgmt_TqCtrl_8bit, handle-invalid=DONT-INVALIDATE}
      data tec_ErrMgmt_TqCtrl_8bit: type=uint8
    IF_ErrMgmt_VehSpdLmt_8bit: invalidation-policy{data-element=tec_ErrMgmt_VehSpdLmt_8bit, handle-invalid=DONT-INVALIDATE}
      data tec_ErrMgmt_VehSpdLmt_8bit: type=uint8
    IF_ErrMgmt_VehSpdLmt_kph: invalidation-policy{data-element=tec_ErrMgmt_VehSpdLmt_kph, handle-invalid=DONT-INVALIDATE}
      data tec_ErrMgmt_VehSpdLmt_kph: type=float32
    IF_GearMgmt_ActGear_Enum: invalidation-policy{data-element=tec_GearMgmt_ActGear_Enum, handle-invalid=DONT-INVALIDATE}
      data tec_GearMgmt_ActGear_Enum: type=uint8
    IF_GearMgmt_TarGearPInhbTq_Flg: invalidation-policy{data-element=tec_GearMgmt_TarGearPInhbTq_Flg, handle-invalid=DONT-INVALIDATE}
      data tec_GearMgmt_TarGearPInhbTq_Flg: type=boolean
    IF_HvMgmt_MCUReqSts_Enum: invalidation-policy{data-element=tec_HvMgmt_MCUReqSts_Enum, handle-invalid=DONT-INVALIDATE}
      data tec_HvMgmt_MCUReqSts_Enum: type=uint8
    IF_ModMgmt_ActDrvMod_Enum: invalidation-policy{data-element=tec_ModMgmt_ActDrvMod_Enum, handle-invalid=DONT-INVALIDATE}
      data tec_ModMgmt_ActDrvMod_Enum: type=uint8
    IF_ModMgmt_HvSts_Enum: invalidation-policy{data-element=tec_ModMgmt_HvSts_Enum, handle-invalid=DONT-INVALIDATE}
      data tec_ModMgmt_HvSts_Enum: type=uint8
    IF_TorqPahMgmt_DesCoorTq_Nm: invalidation-policy{data-element=tec_TorqPahMgmt_DesCoorTq_Nm, handle-invalid=DONT-INVALIDATE}
      data tec_TorqPahMgmt_DesCoorTq_Nm: type=float32
    IF_TorqPahMgmt_DesFildTq_Nm: invalidation-policy{data-element=tec_TorqPahMgmt_DesFildTq_Nm, handle-invalid=DONT-INVALIDATE}
      data tec_TorqPahMgmt_DesFildTq_Nm: type=float32
    IF_TorqPahMgmt_DesLpFildTq_Nm: invalidation-policy{data-element=tec_TorqPahMgmt_DesLpFildTq_Nm, handle-invalid=DONT-INVALIDATE}
      data tec_TorqPahMgmt_DesLpFildTq_Nm: type=float32
    IF_TorqPahMgmt_DesMotSpd_rpm: invalidation-policy{data-element=tec_TorqPahMgmt_DesMotSpd_rpm, handle-invalid=DONT-INVALIDATE}
      data tec_TorqPahMgmt_DesMotSpd_rpm: type=float32
    IF_TorqPahMgmt_DesMotTq_Nm: invalidation-policy{data-element=tec_TorqPahMgmt_DesMotTq_Nm, handle-invalid=DONT-INVALIDATE}
      data tec_TorqPahMgmt_DesMotTq_Nm: type=float32
    IF_TorqPahMgmt_EmacDynMaxTq_Nm: invalidation-policy{data-element=tec_TorqPahMgmt_EmacDynMaxTq_Nm, handle-invalid=DONT-INVALIDATE}
      data tec_TorqPahMgmt_EmacDynMaxTq_Nm: type=float32
    IF_TorqPahMgmt_EmacDynMinTq_Nm: invalidation-policy{data-element=tec_TorqPahMgmt_EmacDynMinTq_Nm, handle-invalid=DONT-INVALIDATE}
      data tec_TorqPahMgmt_EmacDynMinTq_Nm: type=float32
    IF_TorqPahMgmt_EmacQstyMaxTq_Nm: invalidation-policy{data-element=tec_TorqPahMgmt_EmacQstyMaxTq_Nm, handle-invalid=DONT-INVALIDATE}
      data tec_TorqPahMgmt_EmacQstyMaxTq_Nm: type=float32
    IF_TorqPahMgmt_EmacQstyMinTq_Nm: invalidation-policy{data-element=tec_TorqPahMgmt_EmacQstyMinTq_Nm, handle-invalid=DONT-INVALIDATE}
      data tec_TorqPahMgmt_EmacQstyMinTq_Nm: type=float32
    IF_TorqPahMgmt_FwdMaxSpdSts_Flg: invalidation-policy{data-element=tec_TorqPahMgmt_FwdMaxSpdSts_Flg, handle-invalid=DONT-INVALIDATE}
      data tec_TorqPahMgmt_FwdMaxSpdSts_Flg: type=boolean
    IF_TorqPahMgmt_FwdMaxVehSpd_kph: invalidation-policy{data-element=tec_TorqPahMgmt_FwdMaxVehSpd_kph, handle-invalid=DONT-INVALIDATE}
      data tec_TorqPahMgmt_FwdMaxVehSpd_kph: type=float32
    IF_TorqPahMgmt_IBSIntvTqSts_Enum: invalidation-policy{data-element=tec_TorqPahMgmt_IBSIntvTqSts_Enum, handle-invalid=DONT-INVALIDATE}
      data tec_TorqPahMgmt_IBSIntvTqSts_Enum: type=uint8
    IF_TorqPahMgmt_ReqMotDampSts_Enum: invalidation-policy{data-element=tec_TorqPahMgmt_ReqMotDampSts_Enum, handle-invalid=DONT-INVALIDATE}
      data tec_TorqPahMgmt_ReqMotDampSts_Enum: type=uint8
    IF_TorqPahMgmt_ReqMotDampThdTq_Nm: invalidation-policy{data-element=tec_TorqPahMgmt_ReqMotDampThdTq_Nm, handle-invalid=DONT-INVALIDATE}
      data tec_TorqPahMgmt_ReqMotDampThdTq_Nm: type=float32
    IF_TorqPahMgmt_TramProtdLimMaxTq_Nm: invalidation-policy{data-element=IF_TorqPahMgmt_TramProtdLimMaxTq_Nm/tec_TorqPahMgmt_TramProtdLmtMaxTq_Nm, handle-invalid=DONT-INVALIDATE}
      data tec_TorqPahMgmt_TramProtdLmtMaxTq_Nm: type=float32
    IF_TorqPahMgmt_TramProtdLimMinTq_Nm: invalidation-policy{data-element=IF_TorqPahMgmt_TramProtdLimMinTq_Nm/tec_TorqPahMgmt_TramProtdLmtMinTq_Nm, handle-invalid=DONT-INVALIDATE}
      data tec_TorqPahMgmt_TramProtdLmtMinTq_Nm: type=float32
    IF_TorqPahMgmt_TramProtdLmtMaxTq_Nm: invalidation-policy{data-element=IF_TorqPahMgmt_TramProtdLmtMaxTq_Nm/tec_TorqPahMgmt_TramProtdLmtMaxTq_Nm, handle-invalid=DONT-INVALIDATE}
      data tec_TorqPahMgmt_TramProtdLmtMaxTq_Nm: type=float32
    IF_TorqPahMgmt_TramProtdLmtMinTq_Nm: invalidation-policy{data-element=IF_TorqPahMgmt_TramProtdLmtMinTq_Nm/tec_TorqPahMgmt_TramProtdLmtMinTq_Nm, handle-invalid=DONT-INVALIDATE}
      data tec_TorqPahMgmt_TramProtdLmtMinTq_Nm: type=float32
    IF_TorqPahMgmt_VehSpdLmtSts_Flg: invalidation-policy{data-element=tec_TorqPahMgmt_VehSpdLmtSts_Flg, handle-invalid=DONT-INVALIDATE}
      data tec_TorqPahMgmt_VehSpdLmtSts_Flg: type=boolean
    IF_TorqPahMgmt_VehSpdLmtTq_Nm: invalidation-policy{data-element=tec_TorqPahMgmt_VehSpdLmtTq_Nm, handle-invalid=DONT-INVALIDATE}
      data tec_TorqPahMgmt_VehSpdLmtTq_Nm: type=float32
    IF_VehMot_Acclr2Tq_Nm: invalidation-policy{data-element=tec_VehMot_Acclr2Tq_Nm, handle-invalid=DONT-INVALIDATE}
      data tec_VehMot_Acclr2Tq_Nm: type=float32
    IF_VehMot_VehDragTq_Nm: invalidation-policy{data-element=tec_VehMot_VehDragTq_Nm, handle-invalid=DONT-INVALIDATE}
      data tec_VehMot_VehDragTq_Nm: type=float32
    IF_VehMot_VehSpd_kph: invalidation-policy{data-element=tec_VehMot_VehSpd_kph, handle-invalid=DONT-INVALIDATE}
      data tec_VehMot_VehSpd_kph: type=float32
    IF_VehMot_VehSpdAcclr_mps2q: invalidation-policy{data-element=tec_VehMot_VehSpdAcclr_mps2q, handle-invalid=DONT-INVALIDATE}
      data tec_VehMot_VehSpdAcclr_mps2q: type=float32
    IF_VehMot_VehSpdVld_Flg: invalidation-policy{data-element=tec_VehMot_VehSpdVld_Flg, handle-invalid=DONT-INVALIDATE}
      data tec_VehMot_VehSpdVld_Flg: type=boolean
